VERSION "HIPBNYYYYYYYYYYYYYYYYYYYYYYYYYYYNNNNNNNNNN/4/%%%/4/'%**4NNN///"

NS_ :

BS_:

BU_: BCM CLU ECS TPMS SCC EPB ESC PSB ODS DATC LKAS SAS SPAS MDPS TESTER IBOX ACU ABS TCU ECU
VAL_TABLE_ vt_CF_Clu_FuelDispLvl 8 "Level 7" 15 "Invalid(Error)" 14 "Reserved" 13 "Level 12" 12 "Level 11" 11 "Level 10" 10 "Level 9" 9 "Level 8" 7 "Level 6" 6 "Level 5" 5 "Level 4" 4 "Level 3" 3 "Level 2" 2 "Level 1" 1 "Level 0" 0 "Empty" ;
VAL_TABLE_ vt_CF_Tmu_TempSet 32 "High" 31 "31.5¡É" 30 "31¡É/High" 29 "30.5¡É/89¢µ" 28 "30¡É/88¢µ" 27 "29.5¡É/87¢µ" 26 "29¡É/86¢µ" 25 "28.5¡É/85¢µ" 24 "28¡É/84¢µ" 23 "27.5¡É/83¢µ" 22 "27¡É/82¢µ" 21 "26.5¡É/81¢µ" 20 "26¡É/80¢µ" 19 "25.5¡É/79¢µ" 18 "25¡É/78¢µ" 17 "24.5¡É/77¢µ" 16 "24¡É/76¢µ" 15 "23.5¡É/75¢µ" 14 "23¡É/74¢µ " 13 "22.5¡É/73¢µ " 12 "22¡É/72¢µ " 11 "21.5¡É/71¢µ" 10 "21¡É/70¢µ " 9 "20.5¡É/69¢µ" 8 "20¡É/68¢µ" 7 "19.5¡É/67¢µ" 6 "19¡É/66¢µ " 5 "18.5¡É/65¢µ" 4 "18¡É/64¢µ " 3 "17.5¡É/63¢µ" 2 "Low" 1 "Display" 0 "Blank " ;
VAL_TABLE_ vt_CF_Tmu_TempMd 1 "Fahrenheit Mode" 0 "Centigrade Mode" ;
VAL_TABLE_ vt_CF_Tmu_AirconCtr 1 "Activate Aircon auto control" 0 "Deactivate Aircon auto control" ;
VAL_TABLE_ vt_CF_Tmu_ReqRepCnd 3 "Reserved" 2 "Reprogramming complete" 1 "Reprogramming request" 0 "Normal state" ;
VAL_TABLE_ vt_G_SEL_DISP 15 "Fault" 14 "Intermediate Position" 13 "None-EOL DATA" 12 "Paddle shift(D-position)" 11 "Sub-Rom Communication Error" 10 "Sub-Rom Communication" 9 "Not Display at Cluster" 8 "sports mode/manual shift" 7 "R" 6 "N" 5 "D" 4 "DS MODE" 3 "3" 2 "2" 1 "L" 0 "P" ;
VAL_TABLE_ vt_cf_lkas_sysstate 15 "System Failuure" 14 "System Not Calibrated" 13 "Reserved" 12 "Reserved" 11 "Reserved" 10 "Reserved" 9 "Reserved" 8 "Reserved" 7 "Reserved" 6 "Mode 2 Right Line" 5 "Mode 2 Left Line" 4 "Mode 2 Full Lane" 3 "Mode 1-MDPS Control" 2 "System Unavailable" 1 "Low Vehicle Speed" 0 "System OFF" ;
VAL_TABLE_ vt_ACCFailInfo 3 "SCC Service Required" 2 "System temporairy unavailable" 1 "Performance degredation" 0 "System without error" ;
VAL_TABLE_ vt_CF_Clu_RefDetMod 1 "Refuel detected" 0 "Non refuel detected" ;
VAL_TABLE_ PAS_Seat_Belt_Value 3 "Invalid(IPMmsg02 TIME-OUT)" 2 "Failed" 1 "Unbelted" 0 "Belted" ;
VAL_TABLE_ DRV_Seat_Belt_Value 3 "Invalid(IPMmsg02 TIME-OUT)" 2 "Failed" 1 "Unbelted" 0 "Belted" ;
VAL_TABLE_ CF_Clu_Eco_Value 7 "RED" 3 "YELLOW" 1 "GREEN" ;
VAL_TABLE_ CF_Acu_FltStat_Value 3 "Not used" 2 "Fault dose not exist" 1 "Fault status is historic" 0 "Fault status is active" ;
VAL_TABLE_ CF_SWL_Ind_Value 3 "Not used" 2 "Warning Lamp Flash" 1 "Warning Lamp Off" 0 "Warning Lamp On" ;
VAL_TABLE_ Switch_On_Off 1 "ON" 0 "OFF" ;

BO_ 3221225472 VECTOR__INDEPENDENT_SIG_MSG: 0 Vector__XXX
 SG_ ReqTPMS_B2 : 0|8@1- (1,0) [0|0] "" Vector__XXX

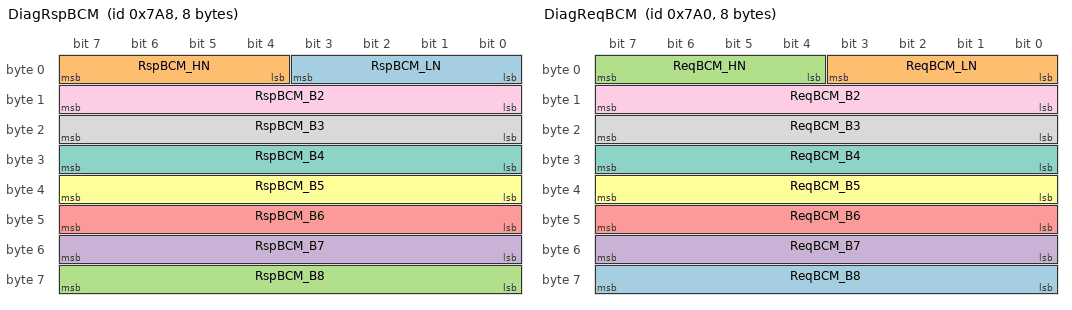
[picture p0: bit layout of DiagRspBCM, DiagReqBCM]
BO_ 1960 DiagRspBCM: 8 BCM
 SG_ RspBCM_LN : 0|4@1+ (1,0) [0|0] ""  IBOX
 SG_ RspBCM_HN : 4|4@1+ (1,0) [0|0] ""  IBOX
 SG_ RspBCM_B8 : 56|8@1+ (1,0) [0|0] ""  IBOX
 SG_ RspBCM_B7 : 48|8@1+ (1,0) [0|0] ""  IBOX
 SG_ RspBCM_B6 : 40|8@1+ (1,0) [0|0] ""  IBOX
 SG_ RspBCM_B5 : 32|8@1+ (1,0) [0|0] ""  IBOX
 SG_ RspBCM_B4 : 24|8@1+ (1,0) [0|0] ""  IBOX
 SG_ RspBCM_B3 : 16|8@1+ (1,0) [0|0] ""  IBOX
 SG_ RspBCM_B2 : 8|8@1+ (1,0) [0|0] ""  IBOX

BO_ 1952 DiagReqBCM: 8 IBOX
 SG_ ReqBCM_B8 : 56|8@1+ (1,0) [0|0] ""  BCM
 SG_ ReqBCM_LN : 0|4@1+ (1,0) [0|0] ""  BCM
 SG_ ReqBCM_HN : 4|4@1+ (1,0) [0|0] ""  BCM
 SG_ ReqBCM_B7 : 48|8@1+ (1,0) [0|0] ""  BCM
 SG_ ReqBCM_B6 : 40|8@1+ (1,0) [0|0] ""  BCM
 SG_ ReqBCM_B5 : 32|8@1+ (1,0) [0|0] ""  BCM
 SG_ ReqBCM_B4 : 24|8@1+ (1,0) [0|0] ""  BCM
 SG_ ReqBCM_B3 : 16|8@1+ (1,0) [0|0] ""  BCM
 SG_ ReqBCM_B2 : 8|8@1+ (1,0) [0|0] ""  BCM

BO_ 128 EMS_DCT11: 8 ECU
 SG_ TQI_ACOR_dct11 : 32|8@1+ (0.390625,0) [0|0] ""  IBOX

BO_ 897 MDPS11: 8 MDPS
 SG_ dummy : 63|1@1+ (1,0) [0|0] ""  IBOX
 SG_ CF_Mdps_WLmp : 0|2@1+ (1,0) [0|0] ""  IBOX

BO_ 832 LKAS11: 8 LKAS
 SG_ dummy : 55|1@1+ (1,0) [0|0] ""  IBOX
 SG_ CF_Lkas_SysState : 2|4@1+ (1,0) [0|0] ""  IBOX

BO_ 1281 ECS11: 3 ECS
 SG_ dummy : 23|1@1+ (1,0) [0|0] ""  IBOX
 SG_ ECS_W_LAMP : 0|1@1+ (1,0) [0|0] ""  IBOX

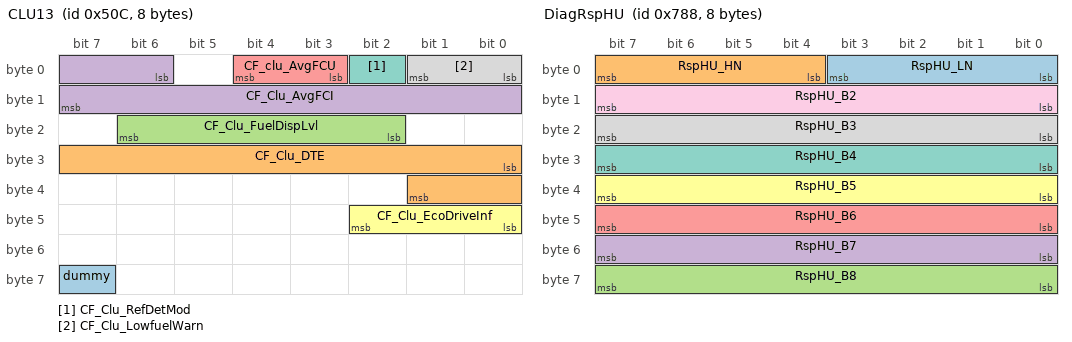
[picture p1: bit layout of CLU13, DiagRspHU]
BO_ 1292 CLU13: 8 CLU
 SG_ dummy : 63|1@1+ (1,0) [0|0] ""  IBOX
 SG_ CF_Clu_DTE : 24|10@1+ (1,0) [0|0] ""  IBOX
 SG_ CF_Clu_FuelDispLvl : 18|5@1+ (1,0) [0|0] ""  IBOX
 SG_ CF_Clu_AvgFCI : 6|10@1+ (0.1,0) [0|102.3] ""  IBOX
 SG_ CF_clu_AvgFCU : 3|2@1+ (1,0) [0|0] ""  IBOX
 SG_ CF_Clu_EcoDriveInf : 40|3@1+ (1,0) [0|0] ""  IBOX
 SG_ CF_Clu_RefDetMod : 2|1@1+ (1,0) [0|0] ""  IBOX
 SG_ CF_Clu_LowfuelWarn : 0|2@1+ (1,0) [0|0] ""  IBOX

BO_ 1456 CLU12: 4 CLU
 SG_ dummy : 31|1@1+ (1,0) [0|0] ""  IBOX
 SG_ CF_Clu_Odometer : 0|24@1+ (0.1,0) [0|1677721.4] ""  IBOX

BO_ 1265 CLU11: 4 CLU
 SG_ dummy : 31|1@1+ (1,0) [0|0] ""  IBOX
 SG_ CF_Clu_SPEED_UNIT : 17|1@1+ (1,0) [0|0] ""  IBOX
 SG_ CF_Clu_Vanz : 8|9@1+ (0.5,0) [0|0] ""  IBOX

BO_ 1928 DiagRspHU: 8 IBOX
 SG_ RspHU_LN : 0|4@1+ (1,0) [0|0] ""  TESTER
 SG_ RspHU_HN : 4|4@1+ (1,0) [0|0] ""  TESTER
 SG_ RspHU_B8 : 56|8@1+ (1,0) [0|0] ""  TESTER
 SG_ RspHU_B7 : 48|8@1+ (1,0) [0|0] ""  TESTER
 SG_ RspHU_B6 : 40|8@1+ (1,0) [0|0] ""  TESTER
 SG_ RspHU_B5 : 32|8@1+ (1,0) [0|0] ""  TESTER
 SG_ RspHU_B4 : 24|8@1+ (1,0) [0|0] ""  TESTER
 SG_ RspHU_B3 : 16|8@1+ (1,0) [0|0] ""  TESTER
 SG_ RspHU_B2 : 8|8@1+ (1,0) [0|0] ""  TESTER

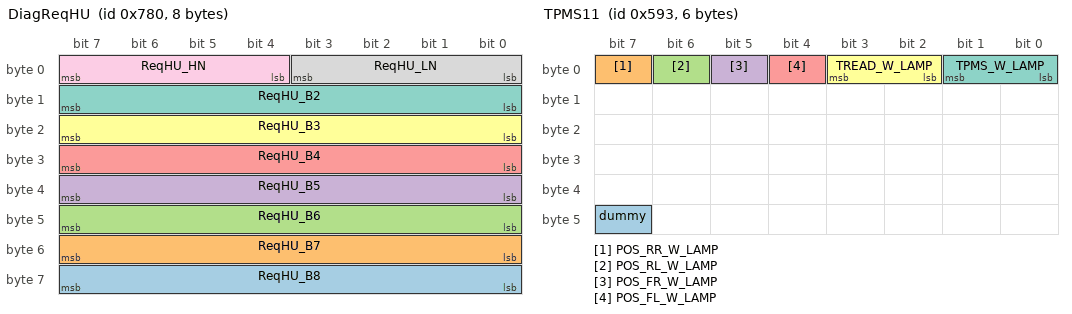
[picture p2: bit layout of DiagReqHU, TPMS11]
BO_ 1920 DiagReqHU: 8 TESTER
 SG_ ReqHU_B8 : 56|8@1+ (1,0) [0|0] ""  IBOX
 SG_ ReqHU_B7 : 48|8@1+ (1,0) [0|0] ""  IBOX
 SG_ ReqHU_B6 : 40|8@1+ (1,0) [0|0] ""  IBOX
 SG_ ReqHU_B5 : 32|8@1+ (1,0) [0|0] ""  IBOX
 SG_ ReqHU_B4 : 24|8@1+ (1,0) [0|0] ""  IBOX
 SG_ ReqHU_B3 : 16|8@1+ (1,0) [0|0] ""  IBOX
 SG_ ReqHU_B2 : 8|8@1+ (1,0) [0|0] ""  IBOX
 SG_ ReqHU_LN : 0|4@1+ (1,0) [0|0] ""  IBOX
 SG_ ReqHU_HN : 4|4@1+ (1,0) [0|0] ""  IBOX

BO_ 1530 ODS11: 8 ODS
 SG_ dummy : 63|1@1+ (1,0) [0|0] ""  IBOX
 SG_ CR_Ecs_ClassStat : 40|8@1+ (1,0) [0|0] ""  IBOX
 SG_ CF_Ods_OccStat : 16|1@1+ (1,0) [0|0] ""  IBOX

BO_ 916 TCS13: 8 ESC
 SG_ dummy : 63|1@1+ (1,0) [0|0] ""  IBOX
 SG_ PBRAKE_ACT : 53|1@1+ (1,0) [0|0] ""  IBOX

BO_ 1287 TCS15: 4 ESC
 SG_ dummy : 31|1@1+ (1,0) [0|0] ""  IBOX
 SG_ TCS_LAMP : 3|2@1+ (1,0) [0|0] ""  IBOX
 SG_ ABS_W_LAMP : 0|1@1+ (1,0) [0|0] ""  IBOX

BO_ 67 DATC13: 8 DATC
 SG_ CF_Datc_TempDispUnit : 0|2@1+ (1,0) [0|0] ""  IBOX
 SG_ CF_Datc_FrontBlwDisp : 60|4@1+ (1,0) [0|0] ""  IBOX
 SG_ CF_Datc_FrDefLed : 14|2@1+ (1,0) [0|0] ""  IBOX

BO_ 66 DATC12: 8 DATC
 SG_ dummy : 63|1@1+ (1,0) [0|0] ""  IBOX
 SG_ CR_Datc_PsTempDispF : 24|8@1+ (1,56) [0|0] ""  IBOX
 SG_ CR_Datc_PsTempDispC : 16|8@1+ (0.5,14) [0|0] ""  IBOX
 SG_ CR_Datc_DrTempDispF : 8|8@1+ (1,56) [0|0] ""  IBOX
 SG_ CR_Datc_DrTempDispC : 0|8@1+ (0.5,14) [14|141.5] ""  IBOX

BO_ 1427 TPMS11: 6 TPMS
 SG_ dummy : 47|1@1+ (1,0) [0|0] ""  IBOX
 SG_ POS_RR_W_LAMP : 7|1@1+ (1,0) [0|0] ""  IBOX
 SG_ POS_RL_W_LAMP : 6|1@1+ (1,0) [0|0] ""  IBOX
 SG_ POS_FR_W_LAMP : 5|1@1+ (1,0) [0|0] ""  IBOX
 SG_ POS_FL_W_LAMP : 4|1@1+ (1,0) [0|0] ""  IBOX
 SG_ TREAD_W_LAMP : 2|2@1+ (1,0) [0|0] ""  IBOX
 SG_ TPMS_W_LAMP : 0|2@1+ (1,0) [0|0] ""  IBOX

BO_ 1057 SCC12: 8 SCC
 SG_ dummy : 63|1@1+ (1,0) [0|0] ""  IBOX
 SG_ ACCMode : 13|2@1+ (1,0) [0|0] ""  IBOX
 SG_ ACCFailInfo : 11|2@1+ (1,0) [0|0] ""  IBOX

BO_ 1168 EPB11: 7 EPB
 SG_ dummy : 55|1@1+ (1,0) [0|0] ""  IBOX
 SG_ EPB_F_LAMP : 4|2@1+ (1,0) [0|0] ""  IBOX
 SG_ EPB_I_LAMP : 0|4@1+ (1,0) [0|0] ""  IBOX

BO_ 16 ACU13: 8 ACU
 SG_ CF_Acu_CshAct : 0|1@1+ (1,0) [0|0] ""  IBOX

BO_ 1440 ACU11: 8 ACU
 SG_ CF_Acu_NumOfFlt : 56|8@1+ (1,0) [0|0] ""  IBOX
 SG_ CF_Acu_Dtc : 40|16@1+ (1,0) [0|0] ""  IBOX
 SG_ CF_Acu_ExtOfSab : 36|2@1+ (1,0) [0|0] ""  IBOX
 SG_ CF_Acu_FltStat : 34|2@1+ (1,0) [0|0] ""  IBOX
 SG_ CF_SWL_Ind : 32|2@1+ (1,0) [0|0] ""  IBOX

BO_ 902 WHL_SPD11: 8 ABS
 SG_ WHL_SPD_RR : 48|14@1+ (0.0312,0) [0|0] ""  IBOX
 SG_ WHL_SPD_RL : 32|14@1+ (0.0312,0) [0|0] ""  IBOX
 SG_ WHL_SPD_FR : 16|14@1+ (0.0312,0) [0|0] ""  IBOX
 SG_ WHL_SPD_FL : 0|14@1+ (0.0312,0) [0|0] ""  IBOX

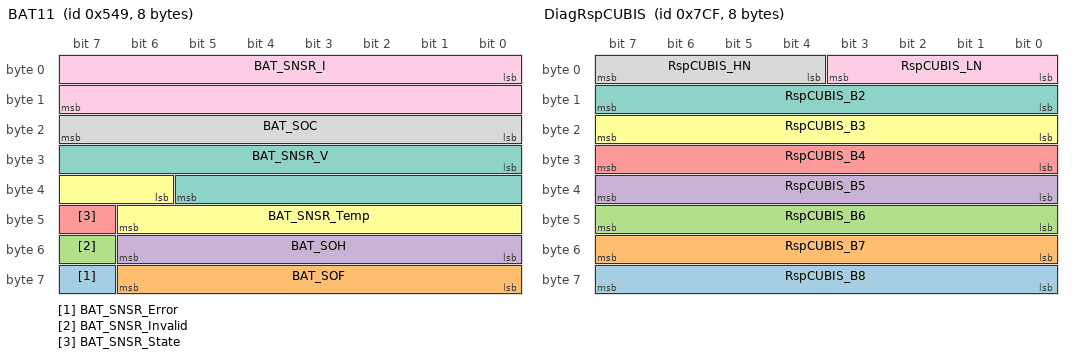
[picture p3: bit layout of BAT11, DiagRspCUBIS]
BO_ 1353 BAT11: 8 ECU
 SG_ BAT_SNSR_Error : 63|1@1+ (1,0) [0|0] ""  IBOX
 SG_ BAT_SOF : 56|7@1+ (1,0) [0|0] ""  IBOX
 SG_ BAT_SNSR_Invalid : 55|1@1+ (1,0) [0|0] ""  IBOX
 SG_ BAT_SOH : 48|7@1+ (1,0) [0|0] ""  IBOX
 SG_ BAT_SNSR_State : 47|1@1+ (1,0) [0|0] ""  IBOX
 SG_ BAT_SNSR_Temp : 38|9@1+ (1,0) [0|0] ""  IBOX
 SG_ BAT_SNSR_V : 24|14@1+ (1,0) [0|0] ""  IBOX
 SG_ BAT_SOC : 16|8@1+ (1,0) [0|0] ""  IBOX
 SG_ BAT_SNSR_I : 0|16@1+ (1,0) [0|0] ""  IBOX

BO_ 688 SAS11: 5 SAS
 SG_ CheckSum : 36|4@1+ (1,0) [0|0] ""  IBOX
 SG_ MsgCount : 32|4@1+ (1,0) [0|0] ""  IBOX
 SG_ SAS_Stat : 24|8@1+ (1,0) [0|0] ""  IBOX
 SG_ SAS_Speed : 16|8@1+ (4,0) [0|1016] ""  IBOX
 SG_ SAS_Angle : 0|16@1+ (0.1,0) [-3276.8|3276.7] ""  IBOX

BO_ 1999 DiagRspCUBIS: 8 IBOX
 SG_ RspCUBIS_B8 : 56|8@1+ (1,0) [0|0] ""  TESTER
 SG_ RspCUBIS_B7 : 48|8@1+ (1,0) [0|0] ""  TESTER
 SG_ RspCUBIS_B6 : 40|8@1+ (1,0) [0|0] ""  TESTER
 SG_ RspCUBIS_B5 : 32|8@1+ (1,0) [0|0] ""  TESTER
 SG_ RspCUBIS_B4 : 24|8@1+ (1,0) [0|0] ""  TESTER
 SG_ RspCUBIS_B3 : 16|8@1+ (1,0) [0|0] ""  TESTER
 SG_ RspCUBIS_B2 : 8|8@1+ (1,0) [0|0] ""  TESTER
 SG_ RspCUBIS_HN : 4|4@1+ (1,0) [0|0] ""  TESTER
 SG_ RspCUBIS_LN : 0|4@1+ (1,0) [0|0] ""  TESTER

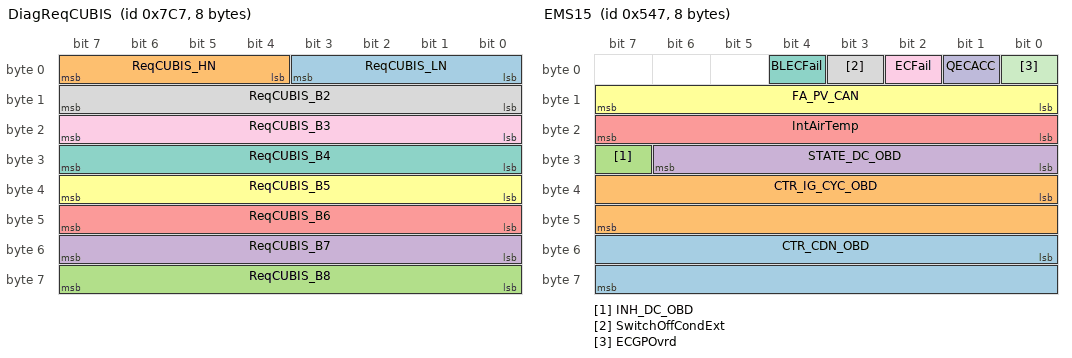
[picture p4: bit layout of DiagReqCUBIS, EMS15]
BO_ 1991 DiagReqCUBIS: 8 TESTER
 SG_ ReqCUBIS_LN : 0|4@1+ (1,0) [0|0] ""  IBOX
 SG_ ReqCUBIS_HN : 4|4@1+ (1,0) [0|0] ""  IBOX
 SG_ ReqCUBIS_B8 : 56|8@1+ (1,0) [0|0] ""  IBOX
 SG_ ReqCUBIS_B7 : 48|8@1+ (1,0) [0|0] ""  IBOX
 SG_ ReqCUBIS_B6 : 40|8@1+ (1,0) [0|0] ""  IBOX
 SG_ ReqCUBIS_B5 : 32|8@1+ (1,0) [0|0] ""  IBOX
 SG_ ReqCUBIS_B4 : 24|8@1+ (1,0) [0|0] ""  IBOX
 SG_ ReqCUBIS_B2 : 8|8@1+ (1,0) [0|0] ""  IBOX
 SG_ ReqCUBIS_B3 : 16|8@1+ (1,0) [0|0] ""  IBOX

BO_ 1367 EngFrzFrm12: 8 ECU
 SG_ dummy : 63|1@1+ (1,0) [0|0] ""  IBOX
 SG_ PID_08h : 16|8@1+ (0.78125,-100) [-100|99.21875] ""  IBOX
 SG_ PID_23h : 40|16@1+ (10,0) [0|655350] ""  IBOX
 SG_ PID_0Bh : 32|8@1+ (1,0) [0|0] ""  IBOX
 SG_ PID_09h : 24|8@1+ (0.78125,-100) [-100|99.22] ""  IBOX
 SG_ PID_07h : 8|8@1+ (0.78125,-100) [-100|99.22] ""  IBOX
 SG_ PID_06h : 0|8@1+ (0.78125,-100) [-100|99.22] ""  IBOX

BO_ 1351 EMS15: 8 ECU
 SG_ CTR_CDN_OBD : 48|16@1+ (1,0) [0|0] ""  IBOX
 SG_ CTR_IG_CYC_OBD : 32|16@1+ (1,0) [0|0] ""  IBOX
 SG_ INH_DC_OBD : 31|1@1+ (1,0) [0|0] ""  IBOX
 SG_ STATE_DC_OBD : 24|7@1+ (1,0) [0|0] ""  IBOX
 SG_ IntAirTemp : 16|8@1+ (0.75,-48) [0|0] ""  IBOX
 SG_ FA_PV_CAN : 8|8@1+ (0.3906,0) [0|0] ""  IBOX
 SG_ BLECFail : 4|1@1+ (1,0) [0|0] ""  IBOX
 SG_ SwitchOffCondExt : 3|1@1+ (1,0) [0|0] ""  IBOX
 SG_ ECFail : 2|1@1+ (1,0) [0|0] ""  IBOX
 SG_ QECACC : 1|1@1+ (1,0) [0|0] ""  IBOX
 SG_ ECGPOvrd : 0|1@1+ (1,0) [0|0] ""  IBOX

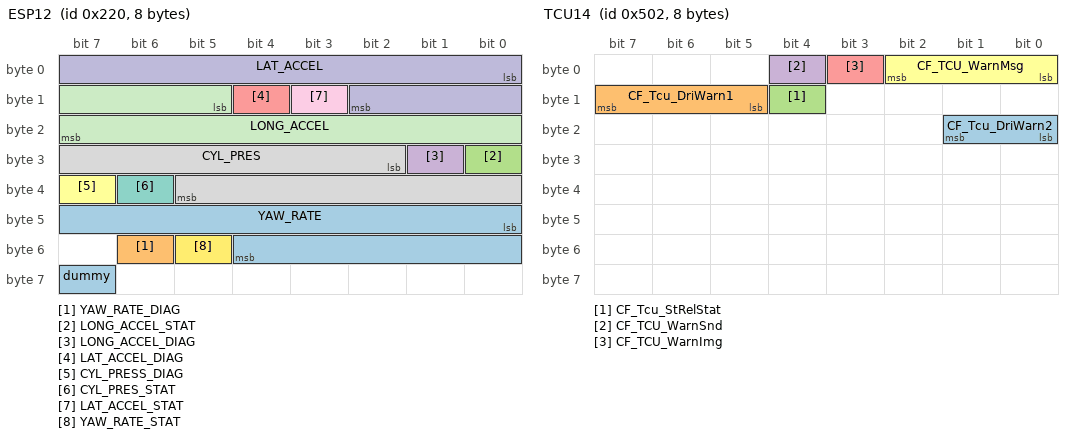
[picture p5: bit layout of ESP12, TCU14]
BO_ 544 ESP12: 8 ESC
 SG_ dummy : 63|1@1+ (1,0) [0|0] ""  IBOX
 SG_ YAW_RATE_DIAG : 54|1@1+ (1,0) [0|0] ""  IBOX
 SG_ LONG_ACCEL_STAT : 24|1@1+ (1,0) [0|0] ""  IBOX
 SG_ LONG_ACCEL_DIAG : 25|1@1+ (1,0) [0|0] ""  IBOX
 SG_ LAT_ACCEL_DIAG : 12|1@1+ (1,0) [0|0] ""  IBOX
 SG_ CYL_PRESS_DIAG : 39|1@1+ (1,0) [0|0] ""  IBOX
 SG_ CYL_PRES_STAT : 38|1@1+ (1,0) [0|0] ""  IBOX
 SG_ CYL_PRES : 26|12@1+ (0.1,0) [0|409.5] ""  IBOX
 SG_ LAT_ACCEL_STAT : 11|1@1+ (1,0) [0|0] ""  IBOX
 SG_ LAT_ACCEL : 0|11@1+ (0.01,-10.23) [-10.23|10.24] ""  IBOX
 SG_ LONG_ACCEL : 13|11@1+ (0.01,-10.23) [-10.23|10.24] ""  IBOX
 SG_ YAW_RATE_STAT : 53|1@1+ (1,0) [0|0] ""  IBOX
 SG_ YAW_RATE : 40|13@1+ (0.01,-40.95) [-40.95|40.96] ""  IBOX

BO_ 899 FATC11: 8 DATC
 SG_ CF_Fatc_PtcRlyStat : 46|1@1+ (1,0) [0|0] ""  IBOX
 SG_ CF_Fatc_defSw : 45|1@1+ (1,0) [0|0] ""  IBOX
 SG_ CF_Fatc_ChkSum : 56|8@1+ (1,0) [0|0] ""  IBOX
 SG_ CF_Fatc_AutoActivation : 44|1@1+ (1,0) [0|0] ""  IBOX
 SG_ CF_Fatc_ActiveEco : 43|1@1+ (1,0) [0|0] ""  IBOX
 SG_ CF_Fatc_Compload : 40|3@1+ (1,0) [0|0] ""  IBOX
 SG_ CR_Fatc_OutTempSns : 32|8@1+ (0.5,-40) [-40|60] ""  IBOX
 SG_ CF_Fatc_MsgCnt : 20|4@1+ (1,0) [0|0] ""  IBOX
 SG_ CF_Fatc_CtrInf : 17|3@1+ (1,0) [0|0] ""  IBOX
 SG_ CF_FATC_Iden : 12|2@1+ (1,0) [0|0] ""  IBOX
 SG_ CF_Fatc_BlwrOn : 11|1@1+ (1,0) [0|0] ""  IBOX
 SG_ CF_Fatc_EcvFlt : 10|1@1+ (1,0) [0|0] ""  IBOX
 SG_ CR_Fatc_OutTemp : 24|8@1+ (0.5,-40) [-40|60] ""  IBOX
 SG_ CF_Fatc_IsgStopReq : 16|1@1+ (1,0) [0|0] ""  IBOX
 SG_ CF_Fatc_EngStartReq : 15|1@1+ (1,0) [0|0] ""  IBOX
 SG_ CF_Fatc_BlwrMax : 14|1@1+ (1,0) [0|0] ""  IBOX
 SG_ CF_Fatc_AcnCltEnRq : 9|1@1+ (1,0) [0|0] ""  IBOX
 SG_ CF_Fatc_AcnRqSwi : 8|1@1+ (1,0) [0|0] ""  IBOX
 SG_ CR_Fatc_TqAcnOut : 0|8@1+ (0.2,0) [0|50.8] ""  IBOX

BO_ 1282 TCU14: 8 TCU
 SG_ CF_Tcu_DriWarn2 : 16|2@1+ (1,0) [0|0] ""  IBOX
 SG_ CF_Tcu_DriWarn1 : 13|3@1+ (1,0) [0|0] ""  IBOX
 SG_ CF_Tcu_StRelStat : 12|1@1+ (1,0) [0|0] ""  IBOX
 SG_ CF_TCU_WarnSnd : 4|1@1+ (1,0) [0|0] ""  IBOX
 SG_ CF_TCU_WarnImg : 3|1@1+ (1,0) [0|0] ""  IBOX
 SG_ CF_TCU_WarnMsg : 0|3@1+ (1,0) [0|0] ""  IBOX

BO_ 275 TCU13: 8 TCU
 SG_ CF_Tcu_SbwPInfo : 56|1@1+ (1,0) [0|0] ""  IBOX
 SG_ CF_Tcu_ShfPatt : 24|4@1+ (1,0) [0|15] ""  IBOX
 SG_ CF_Tcu_ChkSum3 : 60|4@1+ (1,0) [0|0] ""  IBOX
 SG_ CF_Tcu_Alive3 : 58|2@1+ (1,0) [0|0] ""  IBOX
 SG_ CF_Tcu_SptRdy : 48|1@1+ (1,0) [0|0] ""  IBOX
 SG_ CR_Tcu_IsgTgtRPM : 40|8@1+ (20,0) [0|3500] ""  IBOX
 SG_ CF_Tcu_TqGrdLim : 32|8@1+ (10,0) [0|2540] ""  IBOX
 SG_ CF_Tcu_ActEcoRdy : 31|1@1+ (1,0) [0|0] ""  IBOX
 SG_ CF_Tcu_ITPhase : 30|1@1+ (1,0) [0|0] ""  IBOX
 SG_ CF_Tcu_PRelReq : 29|1@1+ (1,0) [0|0] ""  IBOX
 SG_ CF_Tcu_InhVis : 28|1@1+ (1,0) [0|0] ""  IBOX
 SG_ CF_Tcu_TarGr : 20|4@1+ (1,0) [0|0] ""  IBOX
 SG_ CF_Tcu_NCStat : 18|2@1+ (1,0) [0|0] ""  IBOX
 SG_ CF_Tcu_BkeOnReq : 16|2@1+ (1,0) [0|0] ""  IBOX
 SG_ CF_Tcu_IsgInhib : 15|1@1+ (1,0) [0|0] ""  IBOX
 SG_ SLOPE_TCU : 8|6@1+ (0.5,-16) [-16|15.5] ""  IBOX
 SG_ CF_Tcu_InhCda : 14|1@1+ (1,0) [0|0] ""  IBOX
 SG_ N_TGT_LUP : 0|8@1+ (10,500) [500|3040] ""  IBOX

BO_ 512 EMS20: 6 ECU
 SG_ dummy : 47|1@1+ (1,0) [0|0] ""  IBOX
 SG_ CF_Ems_PumpTPres : 16|8@1+ (3.137254902,0) [0|800] ""  IBOX
 SG_ FCO : 0|16@1+ (0.128,0) [0|8388.48] "§¡"  IBOX

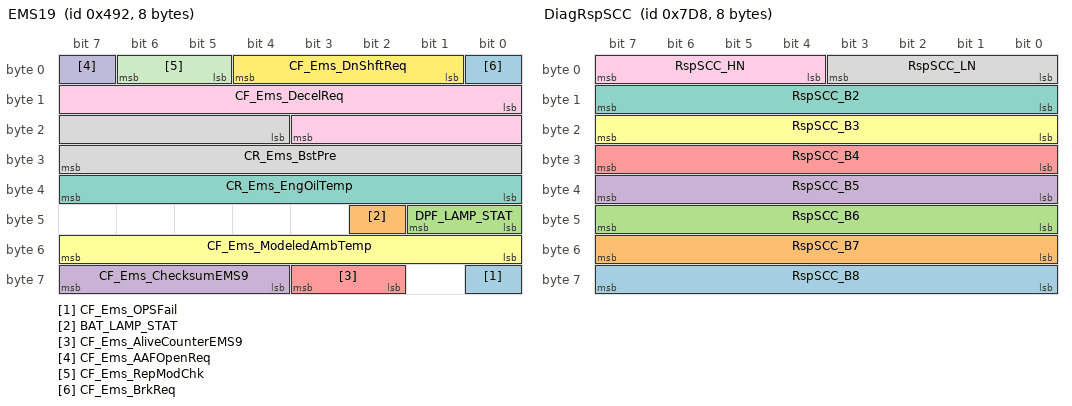
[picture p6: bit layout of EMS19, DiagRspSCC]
BO_ 1170 EMS19: 8 ECU
 SG_ CF_Ems_OPSFail : 56|1@1+ (1,0) [0|0] ""  IBOX
 SG_ BAT_LAMP_STAT : 42|1@1+ (1,0) [0|0] ""  IBOX
 SG_ DPF_LAMP_STAT : 40|2@1+ (1,0) [0|0] ""  IBOX
 SG_ CF_Ems_ChecksumEMS9 : 60|4@1+ (1,0) [0|15] ""  IBOX
 SG_ CF_Ems_AliveCounterEMS9 : 58|2@1+ (1,0) [0|3] ""  IBOX
 SG_ CF_Ems_ModeledAmbTemp : 48|8@1+ (0.5,-41) [-41|85.5] ""  IBOX
 SG_ CR_Ems_EngOilTemp : 32|8@1+ (0.75,-40) [0|254] ""  IBOX
 SG_ CR_Ems_BstPre : 20|12@1+ (1.322,0) [0|4094] ""  IBOX
 SG_ CF_Ems_DecelReq : 8|12@1+ (0.001,-4.094) [0|0] ""  IBOX
 SG_ CF_Ems_AAFOpenReq : 7|1@1+ (1,0) [0|1] ""  IBOX
 SG_ CF_Ems_RepModChk : 5|2@1+ (1,0) [0|3] ""  IBOX
 SG_ CF_Ems_DnShftReq : 1|4@1+ (1,0) [0|15] ""  IBOX
 SG_ CF_Ems_BrkReq : 0|1@1+ (1,0) [0|1] ""  IBOX

BO_ 2008 DiagRspSCC: 8 SCC
 SG_ RspSCC_B8 : 56|8@1+ (1,0) [0|0] ""  IBOX
 SG_ RspSCC_B7 : 48|8@1+ (1,0) [0|0] ""  IBOX
 SG_ RspSCC_B6 : 40|8@1+ (1,0) [0|0] ""  IBOX
 SG_ RspSCC_B5 : 32|8@1+ (1,0) [0|0] ""  IBOX
 SG_ RspSCC_B4 : 24|8@1+ (1,0) [0|0] ""  IBOX
 SG_ RspSCC_B3 : 16|8@1+ (1,0) [0|0] ""  IBOX
 SG_ RspSCC_B2 : 8|8@1+ (1,0) [0|0] ""  IBOX
 SG_ RspSCC_LN : 0|4@1+ (1,0) [0|0] ""  IBOX
 SG_ RspSCC_HN : 4|4@1+ (1,0) [0|0] ""  IBOX

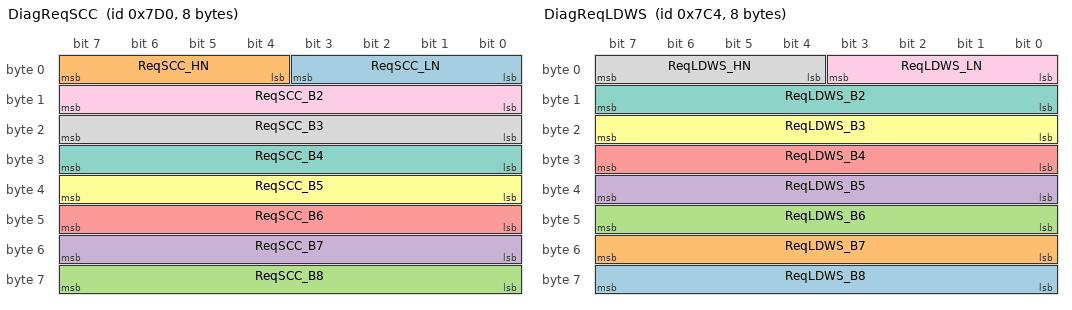
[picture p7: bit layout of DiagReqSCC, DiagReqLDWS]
BO_ 2000 DiagReqSCC: 8 IBOX
 SG_ ReqSCC_LN : 0|4@1+ (1,0) [0|0] ""  SCC
 SG_ ReqSCC_HN : 4|4@1+ (1,0) [0|0] ""  SCC
 SG_ ReqSCC_B8 : 56|8@1+ (1,0) [0|0] ""  SCC
 SG_ ReqSCC_B7 : 48|8@1+ (1,0) [0|0] ""  SCC
 SG_ ReqSCC_B6 : 40|8@1+ (1,0) [0|0] ""  SCC
 SG_ ReqSCC_B5 : 32|8@1+ (1,0) [0|0] ""  SCC
 SG_ ReqSCC_B4 : 24|8@1+ (1,0) [0|0] ""  SCC
 SG_ ReqSCC_B3 : 16|8@1+ (1,0) [0|0] ""  SCC
 SG_ ReqSCC_B2 : 8|8@1+ (1,0) [0|0] ""  SCC

BO_ 1988 DiagReqLDWS: 8 IBOX
 SG_ ReqLDWS_B8 : 56|8@1+ (1,0) [0|0] ""  LKAS
 SG_ ReqLDWS_B7 : 48|8@1+ (1,0) [0|0] ""  LKAS
 SG_ ReqLDWS_B6 : 40|8@1+ (1,0) [0|0] ""  LKAS
 SG_ ReqLDWS_B5 : 32|8@1+ (1,0) [0|0] ""  LKAS
 SG_ ReqLDWS_B4 : 24|8@1+ (1,0) [0|0] ""  LKAS
 SG_ ReqLDWS_B3 : 16|8@1+ (1,0) [0|0] ""  LKAS
 SG_ ReqLDWS_B2 : 8|8@1+ (1,0) [0|0] ""  LKAS
 SG_ ReqLDWS_HN : 4|4@1+ (1,0) [0|0] ""  LKAS
 SG_ ReqLDWS_LN : 0|4@1+ (1,0) [0|0] ""  LKAS

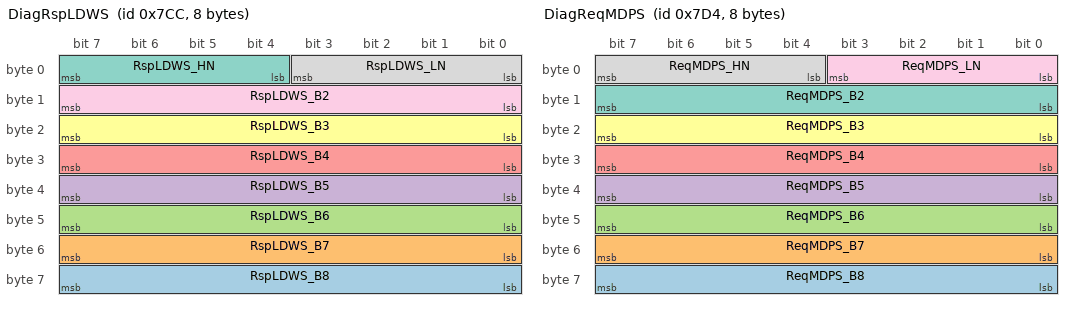
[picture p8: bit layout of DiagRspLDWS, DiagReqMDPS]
BO_ 1996 DiagRspLDWS: 8 LKAS
 SG_ RspLDWS_B8 : 56|8@1+ (1,0) [0|0] ""  IBOX
 SG_ RspLDWS_B7 : 48|8@1+ (1,0) [0|0] ""  IBOX
 SG_ RspLDWS_B6 : 40|8@1+ (1,0) [0|0] ""  IBOX
 SG_ RspLDWS_B5 : 32|8@1+ (1,0) [0|0] ""  IBOX
 SG_ RspLDWS_B4 : 24|8@1+ (1,0) [0|0] ""  IBOX
 SG_ RspLDWS_B3 : 16|8@1+ (1,0) [0|0] ""  IBOX
 SG_ RspLDWS_HN : 4|4@1+ (1,0) [0|0] ""  IBOX
 SG_ RspLDWS_LN : 0|4@1+ (1,0) [0|0] ""  IBOX
 SG_ RspLDWS_B2 : 8|8@1+ (1,0) [0|0] ""  IBOX

BO_ 2004 DiagReqMDPS: 8 IBOX
 SG_ ReqMDPS_B8 : 56|8@1+ (1,0) [0|0] ""  MDPS
 SG_ ReqMDPS_B7 : 48|8@1+ (1,0) [0|0] ""  MDPS
 SG_ ReqMDPS_B6 : 40|8@1+ (1,0) [0|0] ""  MDPS
 SG_ ReqMDPS_B5 : 32|8@1+ (1,0) [0|0] ""  MDPS
 SG_ ReqMDPS_B4 : 24|8@1+ (1,0) [0|0] ""  MDPS
 SG_ ReqMDPS_B3 : 16|8@1+ (1,0) [0|0] ""  MDPS
 SG_ ReqMDPS_B2 : 8|8@1+ (1,0) [0|0] ""  MDPS
 SG_ ReqMDPS_HN : 4|4@1+ (1,0) [0|0] ""  MDPS
 SG_ ReqMDPS_LN : 0|4@1+ (1,0) [0|0] ""  MDPS

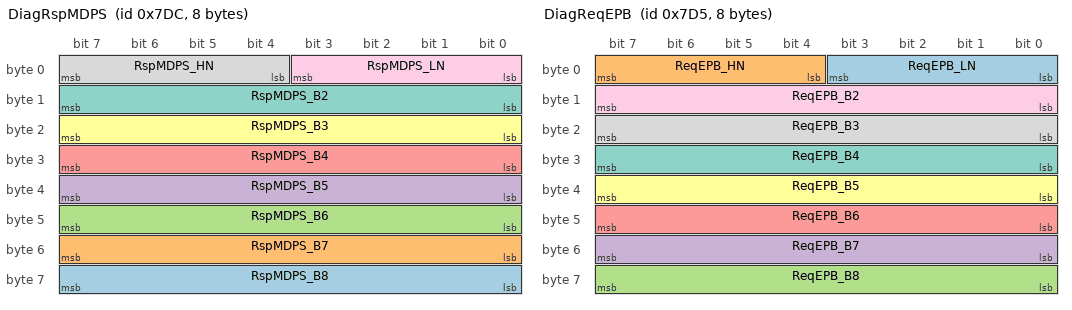
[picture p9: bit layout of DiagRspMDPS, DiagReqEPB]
BO_ 2012 DiagRspMDPS: 8 MDPS
 SG_ RspMDPS_B8 : 56|8@1+ (1,0) [0|0] ""  IBOX
 SG_ RspMDPS_B7 : 48|8@1+ (1,0) [0|0] ""  IBOX
 SG_ RspMDPS_B6 : 40|8@1+ (1,0) [0|0] ""  IBOX
 SG_ RspMDPS_B5 : 32|8@1+ (1,0) [0|0] ""  IBOX
 SG_ RspMDPS_B4 : 24|8@1+ (1,0) [0|0] ""  IBOX
 SG_ RspMDPS_B3 : 16|8@1+ (1,0) [0|0] ""  IBOX
 SG_ RspMDPS_B2 : 8|8@1+ (1,0) [0|0] ""  IBOX
 SG_ RspMDPS_HN : 4|4@1+ (1,0) [0|0] ""  IBOX
 SG_ RspMDPS_LN : 0|4@1+ (1,0) [0|0] ""  IBOX

BO_ 2005 DiagReqEPB: 8 IBOX
 SG_ ReqEPB_LN : 0|4@1+ (1,0) [0|0] ""  EPB
 SG_ ReqEPB_HN : 4|4@1+ (1,0) [0|0] ""  EPB
 SG_ ReqEPB_B8 : 56|8@1+ (1,0) [0|0] ""  EPB
 SG_ ReqEPB_B7 : 48|8@1+ (1,0) [0|0] ""  EPB
 SG_ ReqEPB_B6 : 40|8@1+ (1,0) [0|0] ""  EPB
 SG_ ReqEPB_B5 : 32|8@1+ (1,0) [0|0] ""  EPB
 SG_ ReqEPB_B4 : 24|8@1+ (1,0) [0|0] ""  EPB
 SG_ ReqEPB_B3 : 16|8@1+ (1,0) [0|0] ""  EPB
 SG_ ReqEPB_B2 : 8|8@1+ (1,0) [0|0] ""  EPB

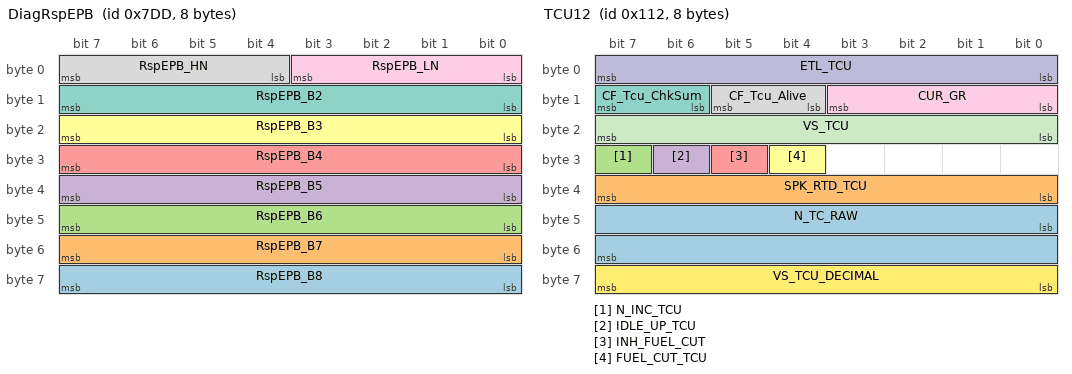
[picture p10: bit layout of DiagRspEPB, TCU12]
BO_ 2013 DiagRspEPB: 8 EPB
 SG_ RspEPB_B8 : 56|8@1+ (1,0) [0|0] ""  IBOX
 SG_ RspEPB_B7 : 48|8@1+ (1,0) [0|0] ""  IBOX
 SG_ RspEPB_B6 : 40|8@1+ (1,0) [0|0] ""  IBOX
 SG_ RspEPB_B5 : 32|8@1+ (1,0) [0|0] ""  IBOX
 SG_ RspEPB_B4 : 24|8@1+ (1,0) [0|0] ""  IBOX
 SG_ RspEPB_B3 : 16|8@1+ (1,0) [0|0] ""  IBOX
 SG_ RspEPB_B2 : 8|8@1+ (1,0) [0|0] ""  IBOX
 SG_ RspEPB_HN : 4|4@1+ (1,0) [0|0] ""  IBOX
 SG_ RspEPB_LN : 0|4@1+ (1,0) [0|0] ""  IBOX

BO_ 274 TCU12: 8 TCU
 SG_ N_TC_RAW : 40|16@1+ (0.25,0) [0|16383.5] ""  IBOX
 SG_ SPK_RTD_TCU : 32|8@1+ (0.375,-23.625) [-15|15] ""  IBOX
 SG_ N_INC_TCU : 31|1@1+ (1,0) [0|0] ""  IBOX
 SG_ IDLE_UP_TCU : 30|1@1+ (1,0) [0|0] ""  IBOX
 SG_ INH_FUEL_CUT : 29|1@1+ (1,0) [0|0] ""  IBOX
 SG_ FUEL_CUT_TCU : 28|1@1+ (1,0) [0|0] ""  IBOX
 SG_ CF_Tcu_ChkSum : 14|2@1+ (1,0) [0|0] ""  IBOX
 SG_ CF_Tcu_Alive : 12|2@1+ (1,0) [0|0] ""  IBOX
 SG_ CUR_GR : 8|4@1+ (1,0) [0|0] ""  IBOX
 SG_ ETL_TCU : 0|8@1+ (2,0) [0|508] ""  IBOX
 SG_ VS_TCU : 16|8@1+ (1,0) [0|255] ""  IBOX
 SG_ VS_TCU_DECIMAL : 56|8@1+ (0.0078,0) [0|0] ""  IBOX

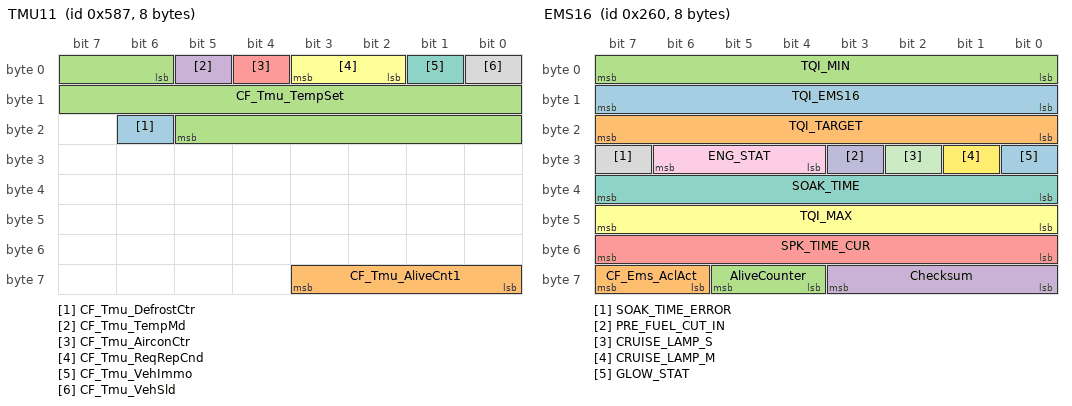
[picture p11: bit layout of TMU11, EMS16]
BO_ 1415 TMU11: 8 IBOX
 SG_ CF_Tmu_DefrostCtr : 22|1@1+ (1,0) [0|1] "" Vector__XXX
 SG_ CF_Tmu_AliveCnt1 : 56|4@1+ (1,0) [0|15] ""  DATC
 SG_ CF_Tmu_TempSet : 6|16@1+ (1,0) [0|255] ""  DATC
 SG_ CF_Tmu_TempMd : 5|1@1+ (1,0) [0|1] ""  DATC
 SG_ CF_Tmu_AirconCtr : 4|1@1+ (1,0) [0|1] ""  DATC
 SG_ CF_Tmu_ReqRepCnd : 2|2@1+ (1,0) [0|3] ""  DATC
 SG_ CF_Tmu_VehImmo : 1|1@1+ (1,0) [0|0] ""  ACU,ABS
 SG_ CF_Tmu_VehSld : 0|1@1+ (1,0) [0|0] ""  ACU,ABS

BO_ 399 EMS_H12: 8 ECU
 SG_ CF_Ems_IsgStat2 : 62|2@1+ (2,0) [0|6] ""  IBOX
 SG_ CF_Ems_EngRunNorm : 61|1@1+ (1,0) [0|1] ""  IBOX
 SG_ CF_Ems_ActEcoAct : 60|1@1+ (1,0) [0|1] ""  IBOX
 SG_ CF_Ems_IdlStpFCO : 58|1@1+ (1,0) [0|1] ""  IBOX
 SG_ CF_Ems_IsgBuz : 57|1@1+ (1,0) [0|1] ""  IBOX
 SG_ CF_Ems_HPresStat : 56|1@1+ (1,0) [0|1] ""  IBOX
 SG_ CF_Ems_FCopen : 59|1@1+ (1,0) [0|0] ""  IBOX
 SG_ CF_Ems_SldPosAct : 55|1@1+ (1,0) [0|0] ""  IBOX
 SG_ CF_Ems_SldAct : 54|1@1+ (1,0) [0|0] ""  IBOX
 SG_ CF_Ems_DesCurGr : 50|4@1+ (1,0) [0|0] ""  IBOX
 SG_ CF_Ems_DownTarGr : 49|1@1+ (1,0) [0|0] ""  IBOX
 SG_ CF_Ems_UpTarGr : 48|1@1+ (1,0) [0|0] ""  IBOX
 SG_ R_NEngIdlTgC : 40|8@1+ (10,0) [0|0] ""  IBOX
 SG_ CF_Ems_EtcLimpMod : 39|1@1+ (1,0) [0|0] ""  IBOX
 SG_ CF_Ems_OilChg : 38|1@1+ (1,0) [0|0] ""  IBOX
 SG_ CF_Ems_IsgStat : 35|3@1+ (1,0) [0|0] ""  IBOX
 SG_ CF_CdsStat : 32|3@1+ (1,0) [0|0] ""  IBOX
 SG_ SLD_VS : 24|8@1+ (1,0) [0|0] ""  IBOX
 SG_ TQI_B : 16|8@1+ (0.390625,0) [0|0] ""  IBOX
 SG_ R_PAcnC : 8|8@1+ (125,0) [0|31875] ""  IBOX
 SG_ R_TqAcnApvC : 0|8@1+ (0.2,0) [0|51] ""  IBOX

BO_ 608 EMS16: 8 ECU
 SG_ TQI_EMS16 : 8|8@1+ (0.390625,0) [0|0] ""  IBOX
 SG_ CF_Ems_AclAct : 62|2@1+ (1,0) [0|0] ""  IBOX
 SG_ AliveCounter : 60|2@1+ (1,0) [0|0] ""  IBOX
 SG_ Checksum : 56|4@1+ (1,0) [0|0] ""  IBOX
 SG_ SPK_TIME_CUR : 48|8@1+ (0.375,-35.625) [-35.625|60] ""  IBOX
 SG_ TQI_MAX : 40|8@1+ (0.390625,0) [0|0] ""  IBOX
 SG_ SOAK_TIME : 32|8@1+ (1,0) [0|0] ""  IBOX
 SG_ SOAK_TIME_ERROR : 31|1@1+ (1,0) [0|0] ""  IBOX
 SG_ ENG_STAT : 28|3@1+ (1,0) [0|0] ""  IBOX
 SG_ PRE_FUEL_CUT_IN : 27|1@1+ (1,0) [0|0] ""  IBOX
 SG_ CRUISE_LAMP_S : 26|1@1+ (1,0) [0|0] ""  IBOX
 SG_ CRUISE_LAMP_M : 25|1@1+ (1,0) [0|0] ""  IBOX
 SG_ GLOW_STAT : 24|1@1+ (1,0) [0|0] ""  IBOX
 SG_ TQI_TARGET : 16|8@1+ (0.390625,0) [0|0] ""  IBOX
 SG_ TQI_MIN : 0|8@1+ (0.390625,0) [0|0] ""  IBOX

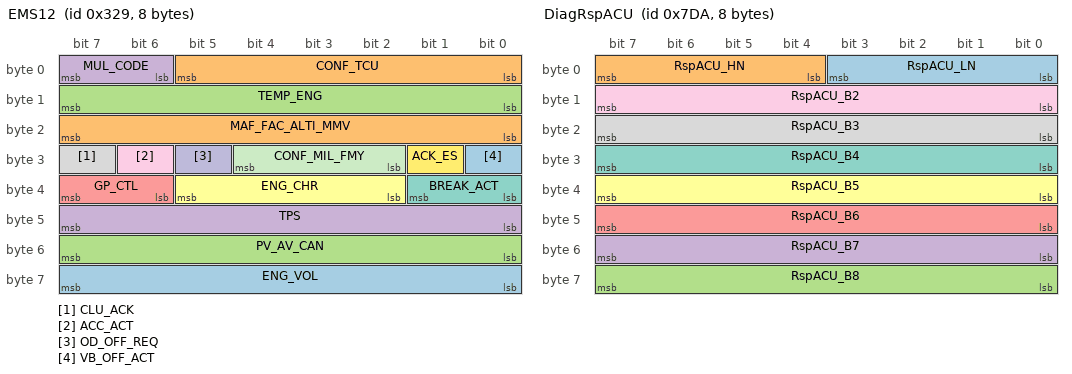
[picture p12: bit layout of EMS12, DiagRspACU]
BO_ 809 EMS12: 8 ECU
 SG_ ENG_VOL : 56|8@1+ (0.1,0) [0|0] ""  IBOX
 SG_ CONF_TCU : 0|6@1+ (1,0) [0|0] ""  IBOX
 SG_ PV_AV_CAN : 48|8@1+ (0.3906,0) [0|0] ""  IBOX
 SG_ TPS : 40|8@1+ (0.4694836,-15.0234742) [0|0] ""  IBOX
 SG_ GP_CTL : 38|2@1+ (1,0) [0|0] ""  IBOX
 SG_ ENG_CHR : 34|4@1+ (1,0) [0|0] ""  IBOX
 SG_ BREAK_ACT : 32|2@1+ (1,0) [0|0] ""  IBOX
 SG_ CLU_ACK : 31|1@1+ (1,0) [0|0] ""  IBOX
 SG_ ACC_ACT : 30|1@1+ (1,0) [0|0] ""  IBOX
 SG_ OD_OFF_REQ : 29|1@1+ (1,0) [0|0] ""  IBOX
 SG_ CONF_MIL_FMY : 26|3@1+ (1,0) [0|0] ""  IBOX
 SG_ ACK_ES : 25|1@1+ (1,0) [0|0] ""  IBOX
 SG_ VB_OFF_ACT : 24|1@1+ (1,0) [0|0] ""  IBOX
 SG_ MAF_FAC_ALTI_MMV : 16|8@1+ (0.00781,0) [0|0] ""  IBOX
 SG_ TEMP_ENG : 8|8@1+ (0.75,-48) [0|0] ""  IBOX
 SG_ MUL_CODE : 6|2@1+ (1,0) [0|0] ""  IBOX

BO_ 2010 DiagRspACU: 8 ACU
 SG_ RspACU_LN : 0|4@1+ (1,0) [0|0] ""  IBOX
 SG_ RspACU_HN : 4|4@1+ (1,0) [0|0] ""  IBOX
 SG_ RspACU_B8 : 56|8@1+ (1,0) [0|0] ""  IBOX
 SG_ RspACU_B7 : 48|8@1+ (1,0) [0|0] ""  IBOX
 SG_ RspACU_B6 : 40|8@1+ (1,0) [0|0] ""  IBOX
 SG_ RspACU_B5 : 32|8@1+ (1,0) [0|0] ""  IBOX
 SG_ RspACU_B4 : 24|8@1+ (1,0) [0|0] ""  IBOX
 SG_ RspACU_B3 : 16|8@1+ (1,0) [0|0] ""  IBOX
 SG_ RspACU_B2 : 8|8@1+ (1,0) [0|0] ""  IBOX

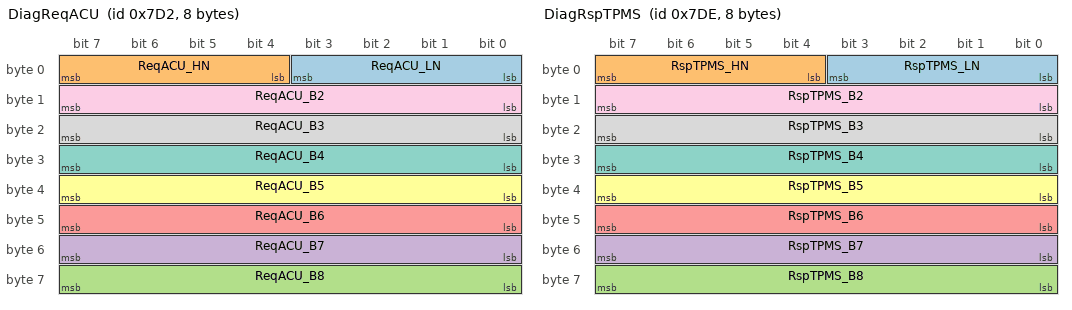
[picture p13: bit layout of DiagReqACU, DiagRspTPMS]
BO_ 2002 DiagReqACU: 8 IBOX
 SG_ ReqACU_LN : 0|4@1+ (1,0) [0|0] ""  ACU
 SG_ ReqACU_HN : 4|4@1+ (1,0) [0|0] ""  ACU
 SG_ ReqACU_B8 : 56|8@1+ (1,0) [0|0] ""  ACU
 SG_ ReqACU_B7 : 48|8@1+ (1,0) [0|0] ""  ACU
 SG_ ReqACU_B6 : 40|8@1+ (1,0) [0|0] ""  ACU
 SG_ ReqACU_B5 : 32|8@1+ (1,0) [0|0] ""  ACU
 SG_ ReqACU_B4 : 24|8@1+ (1,0) [0|0] ""  ACU
 SG_ ReqACU_B3 : 16|8@1+ (1,0) [0|0] ""  ACU
 SG_ ReqACU_B2 : 8|8@1+ (1,0) [0|0] ""  ACU

BO_ 2014 DiagRspTPMS: 8 TPMS
 SG_ RspTPMS_LN : 0|4@1+ (1,0) [0|0] ""  IBOX
 SG_ RspTPMS_HN : 4|4@1+ (1,0) [0|0] ""  IBOX
 SG_ RspTPMS_B8 : 56|8@1+ (1,0) [0|0] ""  IBOX
 SG_ RspTPMS_B7 : 48|8@1+ (1,0) [0|0] ""  IBOX
 SG_ RspTPMS_B6 : 40|8@1+ (1,0) [0|0] ""  IBOX
 SG_ RspTPMS_B5 : 32|8@1+ (1,0) [0|0] ""  IBOX
 SG_ RspTPMS_B4 : 24|8@1+ (1,0) [0|0] ""  IBOX
 SG_ RspTPMS_B3 : 16|8@1+ (1,0) [0|0] ""  IBOX
 SG_ RspTPMS_B2 : 8|8@1+ (1,0) [0|0] ""  IBOX

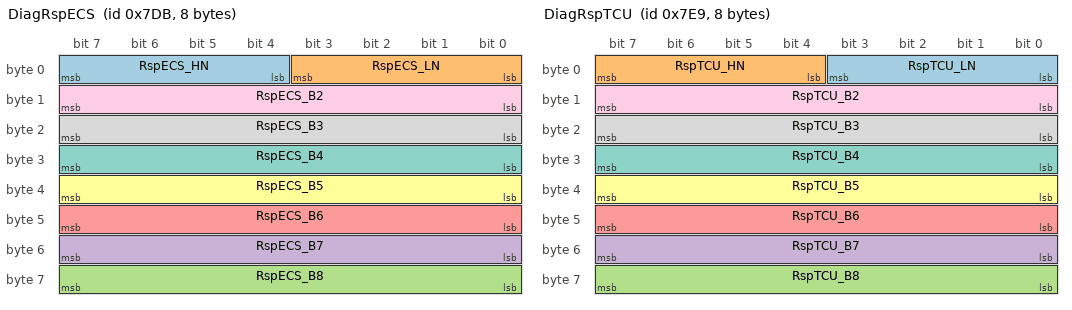
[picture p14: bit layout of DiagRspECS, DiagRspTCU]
BO_ 2011 DiagRspECS: 8 ECS
 SG_ RspECS_HN : 4|4@1+ (1,0) [0|0] ""  IBOX
 SG_ RspECS_LN : 0|4@1+ (1,0) [0|0] ""  IBOX
 SG_ RspECS_B8 : 56|8@1+ (1,0) [0|0] ""  IBOX
 SG_ RspECS_B7 : 48|8@1+ (1,0) [0|0] ""  IBOX
 SG_ RspECS_B6 : 40|8@1+ (1,0) [0|0] ""  IBOX
 SG_ RspECS_B5 : 32|8@1+ (1,0) [0|0] ""  IBOX
 SG_ RspECS_B4 : 24|8@1+ (1,0) [0|0] ""  IBOX
 SG_ RspECS_B3 : 16|8@1+ (1,0) [0|0] ""  IBOX
 SG_ RspECS_B2 : 8|8@1+ (1,0) [0|0] ""  IBOX

BO_ 2025 DiagRspTCU: 8 TCU
 SG_ RspTCU_LN : 0|4@1+ (1,0) [0|0] ""  IBOX
 SG_ RspTCU_HN : 4|4@1+ (1,0) [0|0] ""  IBOX
 SG_ RspTCU_B8 : 56|8@1+ (1,0) [0|0] ""  IBOX
 SG_ RspTCU_B7 : 48|8@1+ (1,0) [0|0] ""  IBOX
 SG_ RspTCU_B6 : 40|8@1+ (1,0) [0|0] ""  IBOX
 SG_ RspTCU_B5 : 32|8@1+ (1,0) [0|0] ""  IBOX
 SG_ RspTCU_B4 : 24|8@1+ (1,0) [0|0] ""  IBOX
 SG_ RspTCU_B3 : 16|8@1+ (1,0) [0|0] ""  IBOX
 SG_ RspTCU_B2 : 8|8@1+ (1,0) [0|0] ""  IBOX

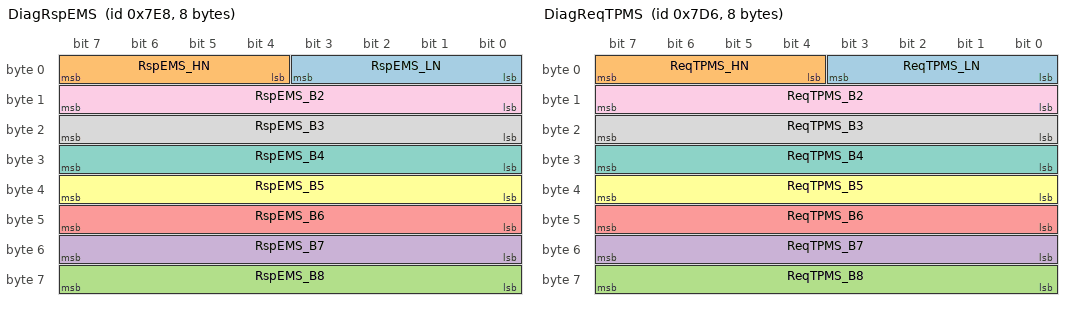
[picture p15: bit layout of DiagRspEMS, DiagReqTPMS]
BO_ 2024 DiagRspEMS: 8 ECU
 SG_ RspEMS_LN : 0|4@1+ (1,0) [0|0] ""  IBOX
 SG_ RspEMS_HN : 4|4@1+ (1,0) [0|0] ""  IBOX
 SG_ RspEMS_B8 : 56|8@1+ (1,0) [0|0] ""  IBOX
 SG_ RspEMS_B7 : 48|8@1+ (1,0) [0|0] ""  IBOX
 SG_ RspEMS_B6 : 40|8@1+ (1,0) [0|0] ""  IBOX
 SG_ RspEMS_B5 : 32|8@1+ (1,0) [0|0] ""  IBOX
 SG_ RspEMS_B4 : 24|8@1+ (1,0) [0|0] ""  IBOX
 SG_ RspEMS_B3 : 16|8@1+ (1,0) [0|0] ""  IBOX
 SG_ RspEMS_B2 : 8|8@1+ (1,0) [0|0] ""  IBOX

BO_ 2006 DiagReqTPMS: 8 IBOX
 SG_ ReqTPMS_LN : 0|4@1+ (1,0) [0|0] ""  TPMS
 SG_ ReqTPMS_HN : 4|4@1+ (1,0) [0|0] ""  TPMS
 SG_ ReqTPMS_B8 : 56|8@1+ (1,0) [0|0] ""  TPMS
 SG_ ReqTPMS_B7 : 48|8@1+ (1,0) [0|0] ""  TPMS
 SG_ ReqTPMS_B6 : 40|8@1+ (1,0) [0|0] ""  TPMS
 SG_ ReqTPMS_B5 : 32|8@1+ (1,0) [0|0] ""  TPMS
 SG_ ReqTPMS_B4 : 24|8@1+ (1,0) [0|0] ""  TPMS
 SG_ ReqTPMS_B3 : 16|8@1+ (1,0) [0|0] ""  TPMS
 SG_ ReqTPMS_B2 : 8|8@1+ (1,0) [0|0] ""  TPMS

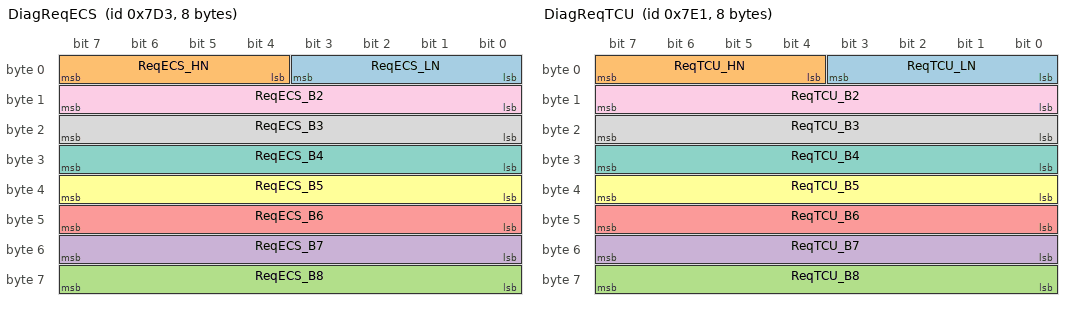
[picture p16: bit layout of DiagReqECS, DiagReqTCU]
BO_ 2003 DiagReqECS: 8 IBOX
 SG_ ReqECS_LN : 0|4@1+ (1,0) [0|0] ""  ECS
 SG_ ReqECS_HN : 4|4@1+ (1,0) [0|0] ""  ECS
 SG_ ReqECS_B8 : 56|8@1+ (1,0) [0|0] ""  ECS
 SG_ ReqECS_B7 : 48|8@1+ (1,0) [0|0] ""  ECS
 SG_ ReqECS_B6 : 40|8@1+ (1,0) [0|0] ""  ECS
 SG_ ReqECS_B5 : 32|8@1+ (1,0) [0|0] ""  ECS
 SG_ ReqECS_B4 : 24|8@1+ (1,0) [0|0] ""  ECS
 SG_ ReqECS_B3 : 16|8@1+ (1,0) [0|0] ""  ECS
 SG_ ReqECS_B2 : 8|8@1+ (1,0) [0|0] ""  ECS

BO_ 2017 DiagReqTCU: 8 IBOX
 SG_ ReqTCU_LN : 0|4@1+ (1,0) [0|0] ""  TCU
 SG_ ReqTCU_HN : 4|4@1+ (1,0) [0|0] ""  TCU
 SG_ ReqTCU_B8 : 56|8@1+ (1,0) [0|0] ""  TCU
 SG_ ReqTCU_B7 : 48|8@1+ (1,0) [0|0] ""  TCU
 SG_ ReqTCU_B6 : 40|8@1+ (1,0) [0|0] ""  TCU
 SG_ ReqTCU_B5 : 32|8@1+ (1,0) [0|0] ""  TCU
 SG_ ReqTCU_B4 : 24|8@1+ (1,0) [0|0] ""  TCU
 SG_ ReqTCU_B3 : 16|8@1+ (1,0) [0|0] ""  TCU
 SG_ ReqTCU_B2 : 8|8@1+ (1,0) [0|0] ""  TCU

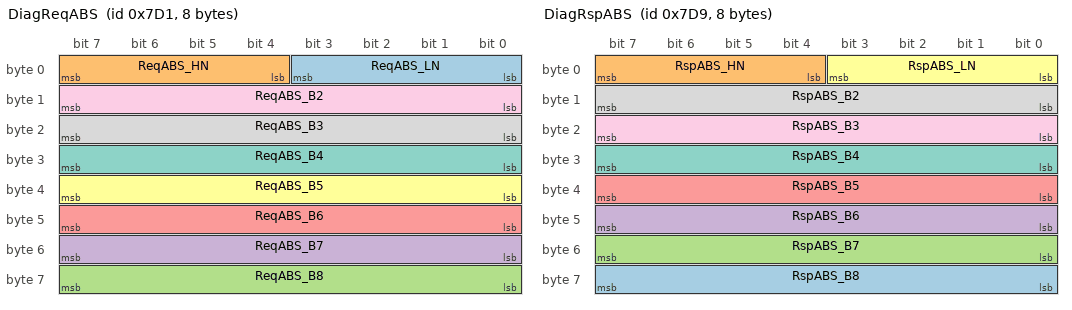
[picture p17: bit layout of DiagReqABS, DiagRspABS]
BO_ 2001 DiagReqABS: 8 IBOX
 SG_ ReqABS_LN : 0|4@1+ (1,0) [0|0] ""  ABS
 SG_ ReqABS_HN : 4|4@1+ (1,0) [0|0] ""  ABS
 SG_ ReqABS_B8 : 56|8@1+ (1,0) [0|0] ""  ABS
 SG_ ReqABS_B7 : 48|8@1+ (1,0) [0|0] ""  ABS
 SG_ ReqABS_B6 : 40|8@1+ (1,0) [0|0] ""  ABS
 SG_ ReqABS_B5 : 32|8@1+ (1,0) [0|0] ""  ABS
 SG_ ReqABS_B4 : 24|8@1+ (1,0) [0|0] ""  ABS
 SG_ ReqABS_B3 : 16|8@1+ (1,0) [0|0] ""  ABS
 SG_ ReqABS_B2 : 8|8@1+ (1,0) [0|0] ""  ABS

BO_ 2009 DiagRspABS: 8 ABS
 SG_ RspABS_B8 : 56|8@1+ (1,0) [0|0] ""  IBOX
 SG_ RspABS_HN : 4|4@1+ (1,0) [0|0] ""  IBOX
 SG_ RspABS_B7 : 48|8@1+ (1,0) [0|0] ""  IBOX
 SG_ RspABS_B6 : 40|8@1+ (1,0) [0|0] ""  IBOX
 SG_ RspABS_B5 : 32|8@1+ (1,0) [0|0] ""  IBOX
 SG_ RspABS_LN : 0|4@1+ (1,0) [0|0] ""  IBOX
 SG_ RspABS_B4 : 24|8@1+ (1,0) [0|0] ""  IBOX
 SG_ RspABS_B2 : 8|8@1+ (1,0) [0|0] ""  IBOX
 SG_ RspABS_B3 : 16|8@1+ (1,0) [0|0] ""  IBOX

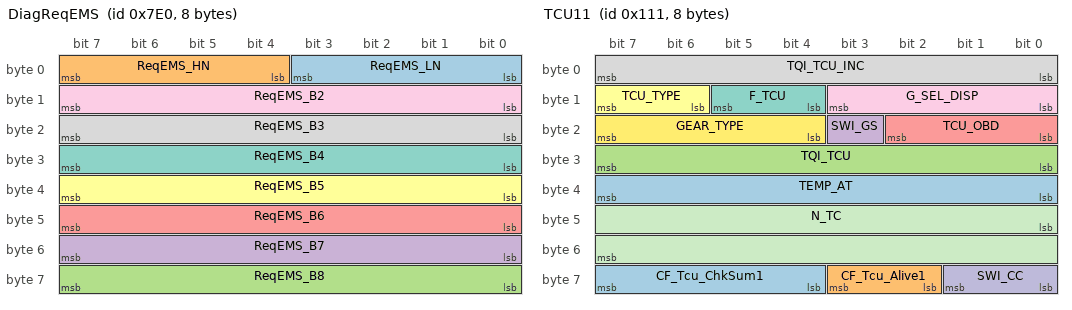
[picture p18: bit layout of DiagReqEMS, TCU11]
BO_ 2016 DiagReqEMS: 8 IBOX
 SG_ ReqEMS_LN : 0|4@1+ (1,0) [0|0] ""  ECU
 SG_ ReqEMS_HN : 4|4@1+ (1,0) [0|0] ""  ECU
 SG_ ReqEMS_B8 : 56|8@1+ (1,0) [0|0] ""  ECU
 SG_ ReqEMS_B7 : 48|8@1+ (1,0) [0|0] ""  ECU
 SG_ ReqEMS_B6 : 40|8@1+ (1,0) [0|0] ""  ECU
 SG_ ReqEMS_B5 : 32|8@1+ (1,0) [0|0] ""  ECU
 SG_ ReqEMS_B4 : 24|8@1+ (1,0) [0|0] ""  ECU
 SG_ ReqEMS_B3 : 16|8@1+ (1,0) [0|0] ""  ECU
 SG_ ReqEMS_B2 : 8|8@1+ (1,0) [0|0] ""  ECU

BO_ 2015 FunctionReq_GST1: 8 TESTER
 SG_ FunctionReq_B8 : 56|8@1+ (1,0) [0|0] ""  IBOX
 SG_ FunctionReq_B7 : 48|8@1+ (1,0) [0|0] ""  IBOX
 SG_ FunctionReq_B6 : 40|8@1+ (1,0) [0|0] ""  IBOX
 SG_ FunctionReq_B5 : 32|8@1+ (1,0) [0|0] ""  IBOX
 SG_ FunctionReq_B4 : 24|8@1+ (1,0) [0|0] ""  IBOX
 SG_ FunctionReq_B3 : 16|8@1+ (1,0) [0|0] ""  IBOX
 SG_ FunctionReq_B2 : 8|8@1+ (1,0) [0|0] ""  IBOX
 SG_ FunctionReq_B1 : 0|8@1+ (1,0) [0|0] ""  IBOX

BO_ 1345 CGW1: 8 CLU
 SG_ CF_Gway_RrSunRoofOpenState : 50|1@1+ (1,0) [0|0] ""  IBOX
 SG_ CF_Gway_WiperMistSw : 47|1@1+ (1,0) [0|0] ""  IBOX
 SG_ CF_Gway_TSigLHSw : 41|1@1+ (1,0) [0|0] ""  IBOX
 SG_ CF_Gway_WiperIntT : 21|3@1+ (1,0) [0|0] ""  IBOX
 SG_ CF_Gway_TurnSigRh : 62|2@1+ (1,0) [0|0] ""  IBOX
 SG_ CF_Gway_ParkBrakeSw : 60|2@1+ (1,0) [0|0] ""  IBOX
 SG_ C_SunRoofOpenState : 57|1@1+ (1,0) [0|0] ""  IBOX
 SG_ CF_Gway_InhibitRMT : 54|2@1+ (1,0) [0|0] ""  IBOX
 SG_ CF_Gway_HLpHighSw : 53|1@1+ (1,0) [0|0] ""  IBOX
 SG_ CF_Gway_HBAControlMode : 52|1@1+ (1,0) [0|0] ""  IBOX
 SG_ CF_Gway_PassingSW : 51|1@1+ (1,0) [0|0] ""  IBOX
 SG_ CF_Gway_PassiveAccessUnlock : 48|2@1+ (1,0) [0|0] ""  IBOX
 SG_ CF_Gway_PassiveAccessLock : 45|2@1+ (1,0) [0|0] ""  IBOX
 SG_ CF_Gway_StarterRlyState : 44|1@1+ (1,0) [0|0] ""  IBOX
 SG_ CF_Gway_DriveTypeOption : 43|1@1+ (1,0) [0|0] ""  IBOX
 SG_ CF_Gway_TSigRHSw : 42|1@1+ (1,0) [0|0] ""  IBOX
 SG_ CF_Gway_Frt_Fog_Act : 40|1@1+ (1,0) [0|0] ""  IBOX
 SG_ CF_Gway_LightSwState : 38|2@1+ (1,0) [0|0] ""  IBOX
 SG_ CF_Gway_ALightStat : 37|1@1+ (1,0) [0|0] ""  IBOX
 SG_ CF_Gway_DefoggerRly : 36|1@1+ (1,0) [0|0] ""  IBOX
 SG_ CF_Gway_AstDrSw : 35|1@1+ (1,0) [0|0] ""  IBOX
 SG_ CF_Gway_HazardSw : 33|2@1+ (1,0) [0|0] ""  IBOX
 SG_ CF_Gway_HeadLampHigh : 32|1@1+ (1,0) [0|0] ""  IBOX
 SG_ CF_Gway_HeadLampLow : 31|1@1+ (1,0) [0|0] ""  IBOX
 SG_ CF_Gway_RainSnsState : 28|3@1+ (1,0) [0|0] ""  IBOX
 SG_ CF_Gway_WiperAutoSw : 27|1@1+ (1,0) [0|0] ""  IBOX
 SG_ CF_Gway_WiperHighSw : 26|1@1+ (1,0) [0|0] ""  IBOX
 SG_ CF_Gway_WiperLowSw : 25|1@1+ (1,0) [0|0] ""  IBOX
 SG_ CF_Gway_WiperIntSw : 24|1@1+ (1,0) [0|0] ""  IBOX
 SG_ CF_Gway_TurnSigLh : 19|2@1+ (1,0) [0|0] ""  IBOX
 SG_ CF_Gway_HoodSw : 17|2@1+ (1,0) [0|0] ""  IBOX
 SG_ CF_Gway_SMKOption : 16|1@1+ (1,0) [0|0] ""  IBOX
 SG_ CF_Gway_AstSeatBeltSw : 14|2@1+ (1,0) [0|0] ""  IBOX
 SG_ CF_Gway_TrunkTgSw : 12|2@1+ (1,0) [0|0] ""  IBOX
 SG_ CF_Gway_DrvSeatBeltSw : 10|2@1+ (1,0) [0|0] ""  IBOX
 SG_ CF_Gway_DrvDrSw : 8|2@1+ (1,0) [0|0] ""  IBOX
 SG_ CF_Gway_DrvKeyUnlockSw : 7|1@1+ (1,0) [0|0] ""  IBOX
 SG_ CF_Gway_DrvKeyLockSw : 6|1@1+ (1,0) [0|0] ""  IBOX
 SG_ CF_Gway_RKECmd : 3|3@1+ (1,0) [0|0] ""  IBOX
 SG_ CF_Gway_IGNSw : 0|3@1+ (1,0) [0|0] ""  IBOX

BO_ 273 TCU11: 8 TCU
 SG_ CF_Tcu_ChkSum1 : 60|4@1+ (1,0) [0|0] ""  IBOX
 SG_ CF_Tcu_Alive1 : 58|2@1+ (1,0) [0|0] ""  IBOX
 SG_ TQI_TCU : 24|8@1+ (0.390625,0) [0|99.609375] ""  IBOX
 SG_ SWI_GS : 19|1@1+ (1,0) [0|0] ""  IBOX
 SG_ TCU_OBD : 16|3@1+ (1,0) [0|7] ""  IBOX
 SG_ TCU_TYPE : 14|2@1+ (1,0) [0|0] ""  IBOX
 SG_ F_TCU : 12|2@1+ (1,0) [0|0] ""  IBOX
 SG_ TQI_TCU_INC : 0|8@1+ (0.390625,0) [0|99.609375] ""  IBOX
 SG_ G_SEL_DISP : 8|4@1+ (1,0) [0|0] ""  IBOX
 SG_ SWI_CC : 56|2@1+ (1,0) [0|0] ""  IBOX
 SG_ N_TC : 40|16@1+ (0.25,0) [0|16383.5] ""  IBOX
 SG_ GEAR_TYPE : 20|4@1+ (1,0) [0|0] ""  IBOX
 SG_ TEMP_AT : 32|8@1+ (1,-40) [-40|215] "¡É"  IBOX

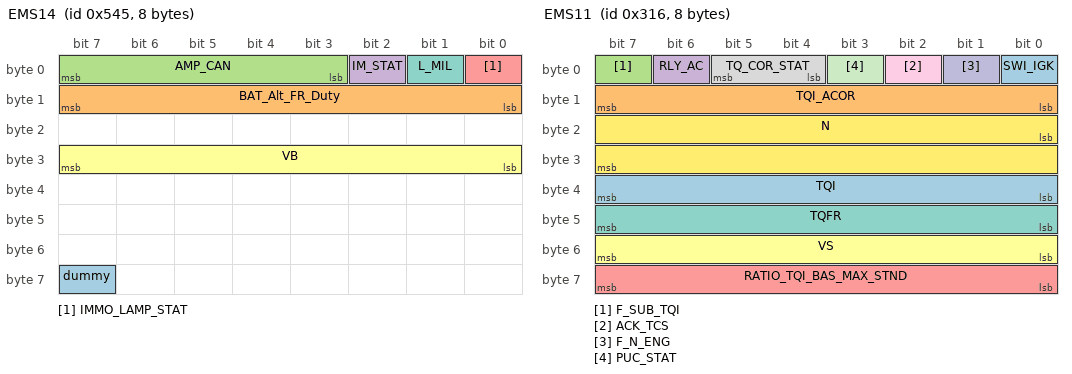
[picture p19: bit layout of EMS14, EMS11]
BO_ 1349 EMS14: 8 ECU
 SG_ dummy : 63|1@1+ (1,0) [0|0] ""  IBOX
 SG_ BAT_Alt_FR_Duty : 8|8@1+ (0.4,0) [0|0] ""  IBOX
 SG_ AMP_CAN : 3|5@1+ (10.731,458.98) [0|0] ""  IBOX
 SG_ IM_STAT : 2|1@1+ (1,0) [0|0] ""  IBOX
 SG_ IMMO_LAMP_STAT : 0|1@1+ (1,0) [0|0] ""  IBOX
 SG_ VB : 24|8@1+ (0.1015,0) [0|25.8825] "V"  IBOX
 SG_ L_MIL : 1|1@1+ (1,0) [0|1] ""  IBOX

BO_ 790 EMS11: 8 ECU
 SG_ TQI : 32|8@1+ (0.390625,0) [0|0] ""  IBOX
 SG_ TQI_ACOR : 8|8@1+ (0.3906,0) [0|0] ""  IBOX
 SG_ F_SUB_TQI : 7|1@1+ (1,0) [0|0] ""  IBOX
 SG_ RLY_AC : 6|1@1+ (1,0) [0|0] ""  IBOX
 SG_ RATIO_TQI_BAS_MAX_STND : 56|8@1+ (0.0078,0) [0|0] ""  IBOX
 SG_ VS : 48|8@1+ (1,0) [0|0] ""  IBOX
 SG_ TQFR : 40|8@1+ (0.390625,0) [0|0] ""  IBOX
 SG_ TQ_COR_STAT : 4|2@1+ (1,0) [0|0] ""  IBOX
 SG_ ACK_TCS : 2|1@1+ (1,0) [0|0] ""  IBOX
 SG_ F_N_ENG : 1|1@1+ (1,0) [0|0] ""  IBOX
 SG_ PUC_STAT : 3|1@1+ (1,0) [0|1] ""  IBOX
 SG_ N : 16|16@1+ (0.25,0) [0|16384] "RPM"  IBOX
 SG_ SWI_IGK : 0|1@1+ (1,0) [0|1] ""  IBOX

BO_TX_BU_ 902 : ESC,ABS;
BO_TX_BU_ 1345 : BCM,CLU;

CM_ BO_ 3221225472 "This is a message for not used signals, created by Vector CANdb++ DBC OLE DB Provider.";
CM_ SG_ 1415 CF_Tmu_AliveCnt1 "Alive Counter";
CM_ SG_ 1415 CF_Tmu_TempSet "Temperature of air conditioner automatic control";
CM_ SG_ 1415 CF_Tmu_TempMd "emperature Unit of air conditioner automatic control
(Centigrade/Fahrenheit)";
CM_ SG_ 1415 CF_Tmu_AirconCtr "Activation of air conditioner automatic control";
CM_ SG_ 1415 CF_Tmu_ReqRepCnd "TMU Request for EMS reprogramming condition";
BA_DEF_ BO_  "GenMsgCycleTimeFast" INT 0 500;
BA_DEF_ BO_  "TpTxIndex" INT 0 255;
BA_DEF_ BU_  "NodeLayerModules" STRING ;
BA_DEF_  "Manufacturer" STRING ;
BA_DEF_ BU_  "ILUsed" ENUM  "No","Yes";
BA_DEF_ SG_  "GenSigStartValue" FLOAT 0 100000000000;
BA_DEF_ SG_  "GenSigSendType" ENUM  "Cyclic","OnWrite","OnWriteWithRepetition","OnChange","OnChangeWithRepetition","IfActive","IfActiveWithRepetition","NoSigSendType","NotUsed","NotUsed","NotUsed","NotUsed","NotUsed";
BA_DEF_ BO_  "GenMsgSendType" ENUM  "Cyclic","NotUsed","NotUsed","NotUsed","NotUsed","Cyclic","NotUsed","IfActive","NoMsgSendType","NotUsed","vector_leerstring";
BA_DEF_ BO_  "GenMsgCycleTime" INT 0 50000;
BA_DEF_ BO_  "GenMsgILSupport" ENUM  "No","Yes";
BA_DEF_ BU_  "NmStationAddress" INT 0 63;
BA_DEF_  "BusType" STRING ;
BA_DEF_  "NmBaseAddress" HEX 0 2047;
BA_DEF_REL_ BU_SG_REL_  "GenSigTimeoutTime" INT 0 3500;
BA_DEF_DEF_  "GenMsgCycleTimeFast" 40;
BA_DEF_DEF_  "TpTxIndex" 0;
BA_DEF_DEF_  "NodeLayerModules" "oseknm01.dll";
BA_DEF_DEF_  "Manufacturer" "HMC";
BA_DEF_DEF_  "ILUsed" "Yes";
BA_DEF_DEF_  "GenSigStartValue" 0;
BA_DEF_DEF_  "GenSigSendType" "NoSigSendType";
BA_DEF_DEF_  "GenMsgSendType" "NoMsgSendType";
BA_DEF_DEF_  "GenMsgCycleTime" 0;
BA_DEF_DEF_  "GenMsgILSupport" "Yes";
BA_DEF_DEF_  "NmStationAddress" 0;
BA_DEF_DEF_  "BusType" "CAN";
BA_DEF_DEF_  "NmBaseAddress" 1024;
BA_DEF_DEF_REL_ "GenSigTimeoutTime" 2000;
BA_ "NodeLayerModules" BU_ BCM "CANoeILNLVector.dll, osek_tp.dll";
BA_ "NodeLayerModules" BU_ CLU "CANoeILNLVector.dll, osek_tp.dll";
BA_ "NodeLayerModules" BU_ ECS "CANoeILNLVector.dll, osek_tp.dll";
BA_ "NodeLayerModules" BU_ TPMS "CANoeILNLVector.dll, osek_tp.dll";
BA_ "NodeLayerModules" BU_ SCC "CANoeILNLVector.dll, osek_tp.dll";
BA_ "NodeLayerModules" BU_ EPB "CANoeILNLVector.dll, osek_tp.dll";
BA_ "NodeLayerModules" BU_ ESC "CANoeILNLVector.dll, osek_tp.dll";
BA_ "NodeLayerModules" BU_ PSB "CANoeILNLVector.dll, osek_tp.dll";
BA_ "NodeLayerModules" BU_ ODS "CANoeILNLVector.dll, osek_tp.dll";
BA_ "NodeLayerModules" BU_ DATC "CANoeILNLVector.dll, osek_tp.dll";
BA_ "NodeLayerModules" BU_ LKAS "CANoeILNLVector.dll, osek_tp.dll";
BA_ "NodeLayerModules" BU_ SAS "CANoeILNLVector.dll, osek_tp.dll";
BA_ "NodeLayerModules" BU_ SPAS "CANoeILNLVector.dll, osek_tp.dll";
BA_ "NodeLayerModules" BU_ MDPS "CANoeILNLVector.dll, osek_tp.dll";
BA_ "NodeLayerModules" BU_ TESTER "CANoeILNLVector.dll, osek_tp.dll";
BA_ "NodeLayerModules" BU_ IBOX "CANoeILNLVector.dll, osek_tp.dll";
BA_ "NodeLayerModules" BU_ ACU "CANoeILNLVector.dll, osek_tp.dll";
BA_ "NodeLayerModules" BU_ ABS "CANoeILNLVector.dll, osek_tp.dll";
BA_ "NodeLayerModules" BU_ TCU "CANoeILNLVector.dll, osek_tp.dll";
BA_ "NodeLayerModules" BU_ ECU "CANoeILNLVector.dll, osek_tp.dll";
BA_ "GenMsgILSupport" BO_ 1960 0;
BA_ "TpTxIndex" BO_ 1960 14;
BA_ "GenMsgILSupport" BO_ 1952 0;
BA_ "TpTxIndex" BO_ 1952 14;
BA_ "GenMsgCycleTime" BO_ 128 10;
BA_ "GenMsgSendType" BO_ 128 0;
BA_ "GenMsgSendType" BO_ 897 0;
BA_ "GenMsgCycleTime" BO_ 897 20;
BA_ "GenMsgSendType" BO_ 832 0;
BA_ "GenMsgCycleTime" BO_ 832 10;
BA_ "GenMsgSendType" BO_ 1281 0;
BA_ "GenMsgCycleTime" BO_ 1281 100;
BA_ "GenMsgSendType" BO_ 1292 0;
BA_ "GenMsgCycleTime" BO_ 1292 100;
BA_ "GenMsgSendType" BO_ 1456 0;
BA_ "GenMsgCycleTime" BO_ 1456 1000;
BA_ "GenMsgCycleTimeFast" BO_ 1265 20;
BA_ "GenMsgSendType" BO_ 1265 0;
BA_ "GenMsgCycleTime" BO_ 1265 20;
BA_ "TpTxIndex" BO_ 1928 13;
BA_ "GenMsgILSupport" BO_ 1928 0;
BA_ "TpTxIndex" BO_ 1920 13;
BA_ "GenMsgILSupport" BO_ 1920 0;
BA_ "GenMsgCycleTime" BO_ 1530 1000;
BA_ "GenMsgSendType" BO_ 1530 0;
BA_ "GenMsgCycleTime" BO_ 916 20;
BA_ "GenMsgSendType" BO_ 916 0;
BA_ "GenMsgSendType" BO_ 1287 0;
BA_ "GenMsgCycleTime" BO_ 1287 100;
BA_ "GenMsgCycleTime" BO_ 67 1000;
BA_ "GenMsgSendType" BO_ 67 0;
BA_ "GenMsgCycleTime" BO_ 66 1000;
BA_ "GenMsgSendType" BO_ 66 0;
BA_ "GenMsgSendType" BO_ 1427 0;
BA_ "GenMsgCycleTime" BO_ 1427 200;
BA_ "GenMsgSendType" BO_ 1057 0;
BA_ "GenMsgCycleTime" BO_ 1057 20;
BA_ "GenMsgCycleTime" BO_ 1168 50;
BA_ "GenMsgSendType" BO_ 1168 0;
BA_ "GenMsgCycleTime" BO_ 1440 1000;
BA_ "GenMsgSendType" BO_ 1440 0;
BA_ "GenMsgSendType" BO_ 902 0;
BA_ "GenMsgCycleTime" BO_ 902 20;
BA_ "GenMsgSendType" BO_ 688 0;
BA_ "GenMsgCycleTime" BO_ 688 10;
BA_ "TpTxIndex" BO_ 1999 12;
BA_ "GenMsgILSupport" BO_ 1999 0;
BA_ "TpTxIndex" BO_ 1991 12;
BA_ "GenMsgILSupport" BO_ 1991 0;
BA_ "GenMsgCycleTime" BO_ 1367 100;
BA_ "GenMsgSendType" BO_ 1367 0;
BA_ "GenMsgCycleTime" BO_ 1351 100;
BA_ "GenMsgSendType" BO_ 1351 0;
BA_ "GenMsgSendType" BO_ 544 0;
BA_ "GenMsgCycleTime" BO_ 544 10;
BA_ "GenMsgCycleTime" BO_ 899 20;
BA_ "GenMsgSendType" BO_ 899 0;
BA_ "GenMsgCycleTime" BO_ 1282 100;
BA_ "GenMsgSendType" BO_ 1282 0;
BA_ "GenMsgCycleTime" BO_ 275 10;
BA_ "GenMsgSendType" BO_ 275 0;
BA_ "GenMsgCycleTime" BO_ 512 10;
BA_ "GenMsgSendType" BO_ 512 0;
BA_ "GenMsgCycleTime" BO_ 1170 50;
BA_ "GenMsgSendType" BO_ 1170 0;
BA_ "GenMsgILSupport" BO_ 2008 0;
BA_ "TpTxIndex" BO_ 2008 10;
BA_ "GenMsgILSupport" BO_ 2000 0;
BA_ "TpTxIndex" BO_ 2000 10;
BA_ "GenMsgILSupport" BO_ 1988 0;
BA_ "TpTxIndex" BO_ 1988 9;
BA_ "GenMsgILSupport" BO_ 1996 0;
BA_ "TpTxIndex" BO_ 1996 9;
BA_ "GenMsgILSupport" BO_ 2004 0;
BA_ "TpTxIndex" BO_ 2004 8;
BA_ "GenMsgILSupport" BO_ 2012 0;
BA_ "TpTxIndex" BO_ 2012 8;
BA_ "GenMsgILSupport" BO_ 2005 0;
BA_ "TpTxIndex" BO_ 2005 7;
BA_ "GenMsgILSupport" BO_ 2013 0;
BA_ "TpTxIndex" BO_ 2013 7;
BA_ "GenMsgSendType" BO_ 274 0;
BA_ "GenMsgCycleTime" BO_ 274 10;
BA_ "GenMsgCycleTime" BO_ 1415 200;
BA_ "GenMsgCycleTimeFast" BO_ 1415 0;
BA_ "GenMsgSendType" BO_ 1415 0;
BA_ "GenMsgSendType" BO_ 399 0;
BA_ "GenMsgCycleTime" BO_ 399 10;
BA_ "GenMsgSendType" BO_ 608 0;
BA_ "GenMsgCycleTime" BO_ 608 10;
BA_ "GenMsgSendType" BO_ 809 0;
BA_ "GenMsgCycleTime" BO_ 809 10;
BA_ "TpTxIndex" BO_ 2010 2;
BA_ "GenMsgILSupport" BO_ 2010 0;
BA_ "TpTxIndex" BO_ 2002 2;
BA_ "GenMsgILSupport" BO_ 2002 0;
BA_ "TpTxIndex" BO_ 2014 6;
BA_ "GenMsgILSupport" BO_ 2014 0;
BA_ "TpTxIndex" BO_ 2011 3;
BA_ "GenMsgILSupport" BO_ 2011 0;
BA_ "TpTxIndex" BO_ 2025 5;
BA_ "GenMsgILSupport" BO_ 2025 0;
BA_ "TpTxIndex" BO_ 2024 4;
BA_ "GenMsgILSupport" BO_ 2024 0;
BA_ "TpTxIndex" BO_ 2006 6;
BA_ "GenMsgILSupport" BO_ 2006 0;
BA_ "TpTxIndex" BO_ 2003 3;
BA_ "GenMsgILSupport" BO_ 2003 0;
BA_ "TpTxIndex" BO_ 2017 5;
BA_ "GenMsgILSupport" BO_ 2017 0;
BA_ "TpTxIndex" BO_ 2001 1;
BA_ "GenMsgILSupport" BO_ 2001 0;
BA_ "TpTxIndex" BO_ 2009 1;
BA_ "GenMsgILSupport" BO_ 2009 0;
BA_ "TpTxIndex" BO_ 2016 4;
BA_ "GenMsgILSupport" BO_ 2016 0;
BA_ "TpTxIndex" BO_ 2015 11;
BA_ "GenMsgILSupport" BO_ 2015 0;
BA_ "GenMsgCycleTime" BO_ 1345 100;
BA_ "GenMsgSendType" BO_ 1345 0;
BA_ "GenMsgCycleTime" BO_ 273 10;
BA_ "GenMsgSendType" BO_ 273 0;
BA_ "GenMsgCycleTime" BO_ 1349 100;
BA_ "GenMsgSendType" BO_ 1349 0;
BA_ "GenMsgCycleTime" BO_ 790 10;
BA_ "GenMsgSendType" BO_ 790 0;
BA_ "GenSigSendType" SG_ 128 TQI_ACOR_dct11 0;
BA_ "GenSigStartValue" SG_ 1440 CF_Acu_ExtOfSab 1;
BA_ "GenSigStartValue" SG_ 688 SAS_Stat 7;
BA_ "GenSigStartValue" SG_ 1367 PID_08h 128;
BA_ "GenSigStartValue" SG_ 1367 PID_09h 128;
BA_ "GenSigStartValue" SG_ 1367 PID_07h 128;
BA_ "GenSigStartValue" SG_ 1367 PID_06h 128;
BA_ "GenSigStartValue" SG_ 1351 IntAirTemp 64;
BA_ "GenSigStartValue" SG_ 544 LAT_ACCEL 1023;
BA_ "GenSigStartValue" SG_ 544 LONG_ACCEL 1023;
BA_ "GenSigStartValue" SG_ 544 YAW_RATE 4095;
BA_ "GenSigStartValue" SG_ 899 CR_Fatc_OutTempSns 80;
BA_ "GenSigStartValue" SG_ 899 CR_Fatc_OutTemp 80;
BA_ "GenSigStartValue" SG_ 275 SLOPE_TCU 32;
BA_ "GenSigSendType" SG_ 1170 CF_Ems_ChecksumEMS9 0;
BA_ "GenSigSendType" SG_ 1170 CF_Ems_AliveCounterEMS9 0;
BA_ "GenSigStartValue" SG_ 1170 CF_Ems_ModeledAmbTemp 82;
BA_ "GenSigSendType" SG_ 1170 CF_Ems_ModeledAmbTemp 0;
BA_ "GenSigStartValue" SG_ 1170 CR_Ems_EngOilTemp 124;
BA_ "GenSigSendType" SG_ 1170 CR_Ems_EngOilTemp 0;
BA_ "GenSigSendType" SG_ 1170 CR_Ems_BstPre 0;
BA_ "GenSigStartValue" SG_ 1170 CF_Ems_DecelReq 4094;
BA_ "GenSigSendType" SG_ 1170 CF_Ems_DecelReq 0;
BA_ "GenSigSendType" SG_ 1170 CF_Ems_AAFOpenReq 0;
BA_ "GenSigSendType" SG_ 1170 CF_Ems_RepModChk 0;
BA_ "GenSigSendType" SG_ 1170 CF_Ems_DnShftReq 0;
BA_ "GenSigSendType" SG_ 1170 CF_Ems_BrkReq 0;
BA_ "GenSigStartValue" SG_ 274 SPK_RTD_TCU 63;
BA_ "GenSigStartValue" SG_ 274 ETL_TCU 127.5;
BA_ "GenSigSendType" SG_ 274 VS_TCU 0;
BA_ "GenSigSendType" SG_ 274 VS_TCU_DECIMAL 0;
BA_ "GenSigSendType" SG_ 399 CF_Ems_HPresStat 0;
BA_ "GenSigSendType" SG_ 399 CF_Ems_FCopen 0;
BA_ "GenSigSendType" SG_ 399 CF_Ems_SldPosAct 0;
BA_ "GenSigSendType" SG_ 399 CF_Ems_SldAct 0;
BA_ "GenSigSendType" SG_ 399 CF_Ems_DesCurGr 0;
BA_ "GenSigSendType" SG_ 399 CF_Ems_DownTarGr 0;
BA_ "GenSigSendType" SG_ 399 CF_Ems_UpTarGr 0;
BA_ "GenSigSendType" SG_ 399 R_NEngIdlTgC 0;
BA_ "GenSigSendType" SG_ 399 CF_Ems_EtcLimpMod 0;
BA_ "GenSigSendType" SG_ 399 CF_Ems_OilChg 0;
BA_ "GenSigSendType" SG_ 399 CF_Ems_IsgStat 0;
BA_ "GenSigSendType" SG_ 399 CF_CdsStat 0;
BA_ "GenSigSendType" SG_ 399 SLD_VS 0;
BA_ "GenSigSendType" SG_ 399 TQI_B 0;
BA_ "GenSigSendType" SG_ 399 R_PAcnC 0;
BA_ "GenSigSendType" SG_ 399 R_TqAcnApvC 0;
BA_ "GenSigSendType" SG_ 608 CF_Ems_AclAct 0;
BA_ "GenSigSendType" SG_ 608 AliveCounter 0;
BA_ "GenSigSendType" SG_ 608 Checksum 0;
BA_ "GenSigSendType" SG_ 608 SPK_TIME_CUR 0;
BA_ "GenSigStartValue" SG_ 608 SPK_TIME_CUR 95;
BA_ "GenSigSendType" SG_ 608 TQI_MAX 0;
BA_ "GenSigSendType" SG_ 608 SOAK_TIME 0;
BA_ "GenSigSendType" SG_ 608 SOAK_TIME_ERROR 0;
BA_ "GenSigSendType" SG_ 608 ENG_STAT 0;
BA_ "GenSigSendType" SG_ 608 PRE_FUEL_CUT_IN 0;
BA_ "GenSigSendType" SG_ 608 CRUISE_LAMP_S 0;
BA_ "GenSigSendType" SG_ 608 CRUISE_LAMP_M 0;
BA_ "GenSigSendType" SG_ 608 GLOW_STAT 0;
BA_ "GenSigSendType" SG_ 608 TQI_TARGET 0;
BA_ "GenSigSendType" SG_ 608 TQI_MIN 0;
BA_ "GenSigSendType" SG_ 809 ENG_VOL 0;
BA_ "GenSigSendType" SG_ 809 PV_AV_CAN 0;
BA_ "GenSigSendType" SG_ 809 TPS 0;
BA_ "GenSigStartValue" SG_ 809 TPS 100.15999323512;
BA_ "GenSigSendType" SG_ 809 GP_CTL 0;
BA_ "GenSigSendType" SG_ 809 ENG_CHR 0;
BA_ "GenSigStartValue" SG_ 809 BREAK_ACT 1;
BA_ "GenSigSendType" SG_ 809 BREAK_ACT 0;
BA_ "GenSigSendType" SG_ 809 CLU_ACK 0;
BA_ "GenSigSendType" SG_ 809 ACC_ACT 0;
BA_ "GenSigSendType" SG_ 809 OD_OFF_REQ 0;
BA_ "GenSigStartValue" SG_ 809 CONF_MIL_FMY 3;
BA_ "GenSigSendType" SG_ 809 CONF_MIL_FMY 0;
BA_ "GenSigSendType" SG_ 809 ACK_ES 0;
BA_ "GenSigSendType" SG_ 809 VB_OFF_ACT 0;
BA_ "GenSigSendType" SG_ 809 MAF_FAC_ALTI_MMV 0;
BA_ "GenSigStartValue" SG_ 809 TEMP_ENG 64;
BA_ "GenSigSendType" SG_ 809 TEMP_ENG 0;
BA_ "GenSigSendType" SG_ 809 MUL_CODE 0;
BA_ "GenSigStartValue" SG_ 273 G_SEL_DISP 9;
BA_ "GenSigSendType" SG_ 273 G_SEL_DISP 0;
BA_ "GenSigSendType" SG_ 273 SWI_CC 0;
BA_ "GenSigSendType" SG_ 273 N_TC 0;
BA_ "GenSigSendType" SG_ 273 GEAR_TYPE 0;
BA_ "GenSigStartValue" SG_ 273 TEMP_AT 40;
BA_ "GenSigSendType" SG_ 273 TEMP_AT 0;
BA_ "GenSigSendType" SG_ 1349 AMP_CAN 0;
BA_ "GenSigSendType" SG_ 1349 IM_STAT 0;
BA_ "GenSigSendType" SG_ 1349 IMMO_LAMP_STAT 0;
BA_ "GenSigSendType" SG_ 1349 VB 0;
BA_ "GenSigSendType" SG_ 1349 L_MIL 0;
BA_ "GenSigSendType" SG_ 790 TQI_ACOR 0;
BA_ "GenSigSendType" SG_ 790 F_SUB_TQI 0;
BA_ "GenSigSendType" SG_ 790 RLY_AC 0;
BA_ "GenSigSendType" SG_ 790 RATIO_TQI_BAS_MAX_STND 0;
BA_ "GenSigSendType" SG_ 790 VS 0;
BA_ "GenSigSendType" SG_ 790 TQFR 0;
BA_ "GenSigSendType" SG_ 790 TQ_COR_STAT 0;
BA_ "GenSigSendType" SG_ 790 ACK_TCS 0;
BA_ "GenSigSendType" SG_ 790 F_N_ENG 0;
BA_ "GenSigSendType" SG_ 790 PUC_STAT 0;
BA_ "GenSigSendType" SG_ 790 N 0;
BA_ "GenSigStartValue" SG_ 790 SWI_IGK 1;
BA_ "GenSigSendType" SG_ 790 SWI_IGK 0;
BA_REL_ "GenSigTimeoutTime" BU_SG_REL_ ABS SG_ 2001 ReqABS_B5 700;
BA_REL_ "GenSigTimeoutTime" BU_SG_REL_ ABS SG_ 2001 ReqABS_B2 700;
VAL_ 1415 CF_Tmu_TempSet 32 "High" 31 "31.5¡É" 30 "31¡É/High" 29 "30.5¡É/89¢µ" 28 "30¡É/88¢µ" 27 "29.5¡É/87¢µ" 26 "29¡É/86¢µ" 25 "28.5¡É/85¢µ" 24 "28¡É/84¢µ" 23 "27.5¡É/83¢µ" 22 "27¡É/82¢µ" 21 "26.5¡É/81¢µ" 20 "26¡É/80¢µ" 19 "25.5¡É/79¢µ" 18 "25¡É/78¢µ" 17 "24.5¡É/77¢µ" 16 "24¡É/76¢µ" 15 "23.5¡É/75¢µ" 14 "23¡É/74¢µ " 13 "22.5¡É/73¢µ " 12 "22¡É/72¢µ " 11 "21.5¡É/71¢µ" 10 "21¡É/70¢µ " 9 "20.5¡É/69¢µ" 8 "20¡É/68¢µ" 7 "19.5¡É/67¢µ" 6 "19¡É/66¢µ " 5 "18.5¡É/65¢µ" 4 "18¡É/64¢µ " 3 "17.5¡É/63¢µ" 2 "Low" 1 "Display" 0 "Blank " ;
VAL_ 1415 CF_Tmu_TempMd 1 "Fahrenheit Mode" 0 "Centigrade Mode" ;
VAL_ 1415 CF_Tmu_AirconCtr 1 "Activate Aircon auto control" 0 "Deactivate Aircon auto control" ;
VAL_ 1415 CF_Tmu_ReqRepCnd 1 "Refuel detected" 0 "Non refuel detected" ;
VAL_ 273 G_SEL_DISP 15 "Fault" 14 "Intermediate Position" 13 "None-EOL DATA" 12 "Paddle shift(D-position)" 11 "Sub-Rom Communication Error" 10 "Sub-Rom Communication" 9 "Not Display at Cluster" 8 "sports mode/manual shift" 7 "R" 6 "N" 5 "D" 4 "DS MODE" 3 "3" 2 "2" 1 "L" 0 "P" ;
